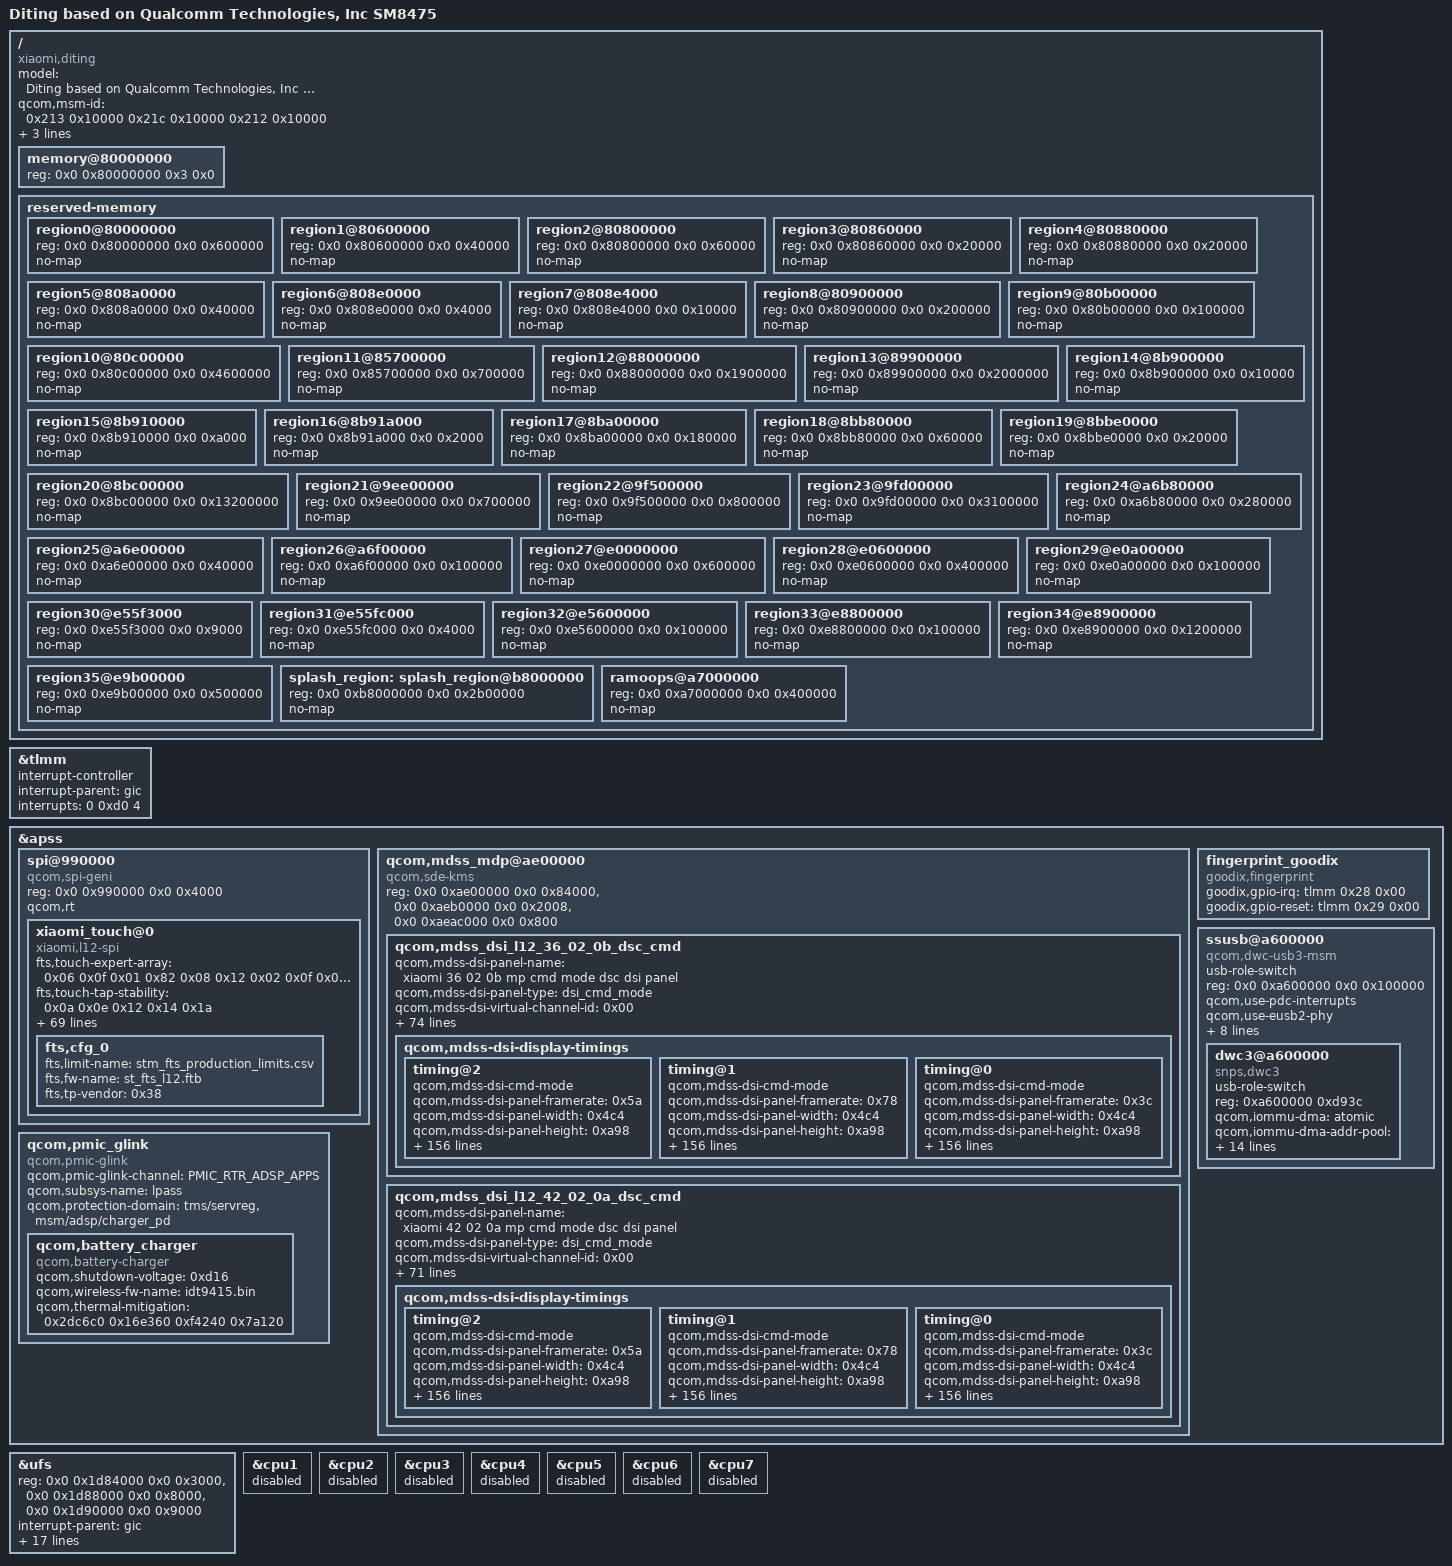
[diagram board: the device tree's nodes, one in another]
/dts-v1/;
/include/ "sm8475.dtsi"
/ {
    model = "Diting based on Qualcomm Technologies, Inc SM8475";
    compatible = "xiaomi,diting", "qcom,cape-mtp", "qcom,cape", "qcom,mtp";
    qcom,msm-id = <0x213 0x10000 0x21c 0x10000 0x212 0x10000>;
    qcom,board-id = <0x10008 0x00>;
    xiaomi,miboard-id = <0x0a 0x00>;
    interrupt-parent = <&gic>;

    /* 此节点供现有 ADT 生成器读取容量。原厂启动时内存并不连续；
       当前单段声明是构建占位，实际内存范围和保留区仍需核实。 */
    memory@80000000 { device_type = "memory"; reg = <0x0 0x80000000 0x3 0x0>; };
    reserved-memory {
        #address-cells = <2>;
        #size-cells = <2>;
        ranges;
        region0@80000000 { reg = <0x0 0x80000000 0x0 0x600000>; no-map; };
        region1@80600000 { reg = <0x0 0x80600000 0x0 0x40000>; no-map; };
        region2@80800000 { reg = <0x0 0x80800000 0x0 0x60000>; no-map; };
        region3@80860000 { reg = <0x0 0x80860000 0x0 0x20000>; no-map; };
        region4@80880000 { reg = <0x0 0x80880000 0x0 0x20000>; no-map; };
        region5@808a0000 { reg = <0x0 0x808a0000 0x0 0x40000>; no-map; };
        region6@808e0000 { reg = <0x0 0x808e0000 0x0 0x4000>; no-map; };
        region7@808e4000 { reg = <0x0 0x808e4000 0x0 0x10000>; no-map; };
        region8@80900000 { reg = <0x0 0x80900000 0x0 0x200000>; no-map; };
        region9@80b00000 { reg = <0x0 0x80b00000 0x0 0x100000>; no-map; };
        region10@80c00000 { reg = <0x0 0x80c00000 0x0 0x4600000>; no-map; };
        region11@85700000 { reg = <0x0 0x85700000 0x0 0x700000>; no-map; };
        region12@88000000 { reg = <0x0 0x88000000 0x0 0x1900000>; no-map; };
        region13@89900000 { reg = <0x0 0x89900000 0x0 0x2000000>; no-map; };
        region14@8b900000 { reg = <0x0 0x8b900000 0x0 0x10000>; no-map; };
        region15@8b910000 { reg = <0x0 0x8b910000 0x0 0xa000>; no-map; };
        region16@8b91a000 { reg = <0x0 0x8b91a000 0x0 0x2000>; no-map; };
        region17@8ba00000 { reg = <0x0 0x8ba00000 0x0 0x180000>; no-map; };
        region18@8bb80000 { reg = <0x0 0x8bb80000 0x0 0x60000>; no-map; };
        region19@8bbe0000 { reg = <0x0 0x8bbe0000 0x0 0x20000>; no-map; };
        region20@8bc00000 { reg = <0x0 0x8bc00000 0x0 0x13200000>; no-map; };
        region21@9ee00000 { reg = <0x0 0x9ee00000 0x0 0x700000>; no-map; };
        region22@9f500000 { reg = <0x0 0x9f500000 0x0 0x800000>; no-map; };
        region23@9fd00000 { reg = <0x0 0x9fd00000 0x0 0x3100000>; no-map; };
        region24@a6b80000 { reg = <0x0 0xa6b80000 0x0 0x280000>; no-map; };
        region25@a6e00000 { reg = <0x0 0xa6e00000 0x0 0x40000>; no-map; };
        region26@a6f00000 { reg = <0x0 0xa6f00000 0x0 0x100000>; no-map; };
        region27@e0000000 { reg = <0x0 0xe0000000 0x0 0x600000>; no-map; };
        region28@e0600000 { reg = <0x0 0xe0600000 0x0 0x400000>; no-map; };
        region29@e0a00000 { reg = <0x0 0xe0a00000 0x0 0x100000>; no-map; };
        region30@e55f3000 { reg = <0x0 0xe55f3000 0x0 0x9000>; no-map; };
        region31@e55fc000 { reg = <0x0 0xe55fc000 0x0 0x4000>; no-map; };
        region32@e5600000 { reg = <0x0 0xe5600000 0x0 0x100000>; no-map; };
        region33@e8800000 { reg = <0x0 0xe8800000 0x0 0x100000>; no-map; };
        region34@e8900000 { reg = <0x0 0xe8900000 0x0 0x1200000>; no-map; };
        region35@e9b00000 { reg = <0x0 0xe9b00000 0x0 0x500000>; no-map; };
        splash_region: splash_region@b8000000 { reg = <0x0 0xb8000000 0x0 0x2b00000>; no-map; };
        ramoops@a7000000 { reg = <0x0 0xa7000000 0x0 0x400000>; no-map; };
    };
};

/* 与本机运行时设备树中的 TLMM 中断控制器配置一致。 */
&tlmm {
    interrupt-controller;
    #interrupt-cells = <2>;
    interrupt-parent = <&gic>;
    interrupts = <0 0xd0 4>;
};

/* Board nodes from dtbo-02-0x0-r0.dtb (Redmi K50 Ultra), merged over the
   stock vendor_boot DTB. SoC containers (GENI SPI, MDSS, pmic_glink) are
   placeholders: only the board children are reproduced. */
&apss {
    spi@990000 {
        compatible = "qcom,spi-geni";
        reg = <0x0 0x990000 0x0 0x4000>;
        reg-names = "se_phys";
        #address-cells = <1>;
        #size-cells = <0>;
        qcom,rt;
        xiaomi_touch@0 {
            fts,touch-expert-array = <0x06 0x0f 0x01 0x82 0x08 0x12 0x02 0x0f 0x01 0x82 0x05 0x12 0x04 0x0f 0x01 0x82 0x04 0x12>;
            fts,touch-tap-stability = <0x0a 0x0e 0x12 0x14 0x1a>;
            fts,touch-aim-sensitivity = <0x0c 0x0a 0x08 0x06 0x04>;
            fts,touch-tap-sensitivity = <0xa0 0x96 0x8c 0x82 0x64>;
            fts,touch-follow-performance = <0x0a 0x0f 0x01 0x08 0x0f 0x01 0x06 0x0f 0x01 0x04 0x0f 0x01 0x02 0x0f 0x01>;
            fts,touch-normal-cornerzone-filter-hor2 = <0x00 0x00 0x405 0x00 0x4c3 0xbe 0x00 0x00 0x00 0x01 0x00 0x00 0x00 0x00 0x00 0x00 0x00 0x02 0x00 0x00 0x00 0x00 0x00 0x00 0x00 0x03 0x405 0x9d9 0x4c3 0xa97 0x00 0x00>;
            fts,touch-normal-cornerzone-filter-hor1 = <0x00 0x00 0x00 0x00 0x00 0x00 0x00 0x00 0x00 0x01 0x00 0x00 0xbe 0xbe 0x00 0x00 0x00 0x02 0x00 0x9d9 0xbe 0xa97 0x00 0x00 0x00 0x03 0x00 0x00 0x00 0x00 0x00 0x00>;
            fts,touch-normal-edgezone-filter-hor = <0x01 0x00 0x00 0x00 0x4c3 0x28 0x00 0x00 0x01 0x01 0x00 0xa6f 0x4c3 0xa97 0x00 0x00 0x01 0x02 0x00 0x00 0x28 0xa97 0x00 0x00 0x01 0x03 0x49b 0x00 0x4c3 0xa97 0x00 0x00>;
            fts,touch-cornerzone-filter-hor2 = <0x00 0x00 0x405 0x00 0x4c3 0xbe 0x00 0x00 0x00 0x01 0x00 0x00 0x00 0x00 0x00 0x00 0x00 0x02 0x00 0x00 0x00 0x00 0x00 0x00 0x00 0x03 0x405 0x9d9 0x4c3 0xa97 0x00 0x00>;
            fts,touch-cornerzone-filter-hor1 = <0x00 0x00 0x00 0x00 0x00 0x00 0x00 0x00 0x00 0x01 0x00 0x00 0xbe 0xbe 0x00 0x00 0x00 0x02 0x00 0x9d9 0xbe 0xa97 0x00 0x00 0x00 0x03 0x00 0x00 0x00 0x00 0x00 0x00>;
            fts,touch-cornerzone-filter-ver = <0x00 0x00 0x00 0x00 0x00 0x00 0x00 0x00 0x00 0x01 0x00 0x00 0x00 0x00 0x00 0x00 0x00 0x02 0x00 0x944 0xa9 0xa97 0x00 0x00 0x00 0x03 0x41a 0x944 0x4c3 0xa97 0x00 0x00>;
            fts,touch-edgezone-filter-hor = <0x01 0x00 0x00 0x00 0x4c3 0x2a 0x00 0x00 0x01 0x01 0x00 0xa6d 0x4c3 0xa97 0x00 0x00 0x01 0x02 0x00 0x00 0x2a 0xa97 0x00 0x00 0x01 0x03 0x499 0x00 0x4c3 0xa97 0x00 0x00>;
            fts,touch-edgezone-filter-ver = <0x01 0x00 0x00 0x00 0x00 0x00 0x00 0x00 0x01 0x01 0x00 0x00 0x00 0x00 0x00 0x00 0x01 0x02 0x00 0x00 0x2a 0xa97 0x00 0x00 0x01 0x03 0x499 0x00 0x4c3 0xa97 0x00 0x00>;
            fts,touch-deadzone-filter-hor = <0x02 0x00 0x00 0x00 0x4c3 0x00 0x00 0x00 0x02 0x01 0x00 0xa97 0x4c3 0xa97 0x00 0x00 0x02 0x02 0x00 0x00 0x00 0xa97 0x00 0x00 0x02 0x03 0x4c3 0x00 0x4c3 0xa97 0x00 0x00>;
            fts,touch-deadzone-filter-ver = <0x02 0x00 0x00 0x00 0x00 0x00 0x00 0x00 0x02 0x01 0x00 0x00 0x00 0x00 0x00 0x00 0x02 0x02 0x00 0x00 0x00 0xa97 0x00 0x00 0x02 0x03 0x4c3 0x00 0x4c3 0xa97 0x00 0x00>;
            fts,cornerfilter-area-step3 = <0x118>;
            fts,cornerfilter-area-step2 = <0xbe>;
            fts,cornerfilter-area-step1 = <0x70>;
            fts,touch-tap-stability-def = <0x03>;
            fts,touch-aim-sensitivity-def = <0x03>;
            fts,touch-tap-sensitivity-def = <0x04>;
            fts,touch-follow-performance-def = <0x03>;
            fts,support-super-resolution = <0x01>;
            fts,config-array-size = <0x01>;
            fts,non-curved-display = <0x01>;
            fts,default-fw-name = "st_fts_l12.ftb";
            fts,fod-y-size = <0x8e8>;
            fts,fod-x-size = <0x8e8>;
            fts,fod-ly = <0x5b04>;
            fts,fod-lx = <0x1360>;
            fts,support-fod = <0x01>;
            fts,y-max = <0x69f0>;
            fts,x-max = <0x2fa8>;
            fts,irq-flags = <0x2008>;
            fts,reset-gpio-name = "fts_rst";
            fts,reset-gpio = <&tlmm 0x14 0x00>;
            fts,reset-gpio-enable;
            fts,irq-gpio-name = "fts_irq";
            fts,irq-gpio = <&tlmm 0x15 0x2008>;
            fts,bus-reg-name = "vdd";
            fts,avdd-gpio = <&tlmm 0x47 0x00>;
            goodix,touch-expert-array = <0x02 0x03 0x02 0x02 0x04 0x03 0x03 0x02 0x03 0x03 0x04 0x02>;
            goodix,config-name = "goodix_cfg_group_l12";
            goodix,firmware-name = "goodix_firmware_l12";
            goodix,panel-max-p = <0x1000>;
            goodix,panel-max-w = <0xff>;
            goodix,panel-max-y = <0x69f0>;
            goodix,panel-max-x = <0x2fa8>;
            goodix,irq-flags = <0x02>;
            goodix,reset-gpio = <&tlmm 0x14 0x00>;
            goodix,irq-gpio = <&tlmm 0x15 0x2008>;
            goodix,iovdd-name = "vdd";
            goodix,avdd-gpio = <&tlmm 0x47 0x00>;
            interrupts = <0x15 0x2008>;
            interrupt-parent = <&tlmm>;
            spi-max-frequency = <0xb71b00>;
            reg = <0x00>;
            compatible = "xiaomi,l12-spi";
            status = "ok";
            fts,cfg_0 {
                fts,limit-name = "stm_fts_production_limits.csv";
                fts,fw-name = "st_fts_l12.ftb";
                fts,tp-vendor = <0x38>;
            };
        };
    };

    qcom,mdss_mdp@ae00000 {
        compatible = "qcom,sde-kms";
        reg = <0x0 0xae00000 0x0 0x84000>,
              <0x0 0xaeb0000 0x0 0x2008>,
              <0x0 0xaeac000 0x0 0x800>;
        reg-names = "mdp_phys", "vbif_phys", "regdma_phys";
        qcom,mdss_dsi_l12_36_02_0b_dsc_cmd {
            qcom,mdss-dsi-panel-name = "xiaomi 36 02 0b mp cmd mode dsc dsi panel";
            qcom,mdss-dsi-panel-type = "dsi_cmd_mode";
            qcom,mdss-dsi-virtual-channel-id = <0x00>;
            qcom,mdss-dsi-stream = <0x00>;
            qcom,mdss-dsi-bpp = <0x1e>;
            qcom,mdss-dsi-color-order = "rgb_swap_rgb";
            qcom,mdss-dsi-underflow-color = <0xff>;
            qcom,mdss-dsi-border-color = <0x00>;
            qcom,dsi-ctrl-num = <0x00>;
            qcom,dsi-phy-num = <0x00>;
            qcom,mdss-dsi-traffic-mode = "burst_mode";
            qcom,mdss-dsi-lane-map = "lane_map_0123";
            qcom,mdss-dsi-bllp-eof-power-mode;
            qcom,mdss-dsi-bllp-power-mode;
            qcom,mdss-dsi-lane-0-state;
            qcom,mdss-dsi-lane-1-state;
            qcom,mdss-dsi-lane-2-state;
            qcom,mdss-dsi-lane-3-state;
            qcom,mdss-dsi-dma-trigger = "trigger_sw";
            qcom,mdss-dsi-mdp-trigger = "none";
            qcom,mdss-dsi-reset-sequence = <0x01 0x0b 0x00 0x01 0x01 0x14>;
            qcom,mdss-pan-physical-width-dimension = <0x2b7>;
            qcom,mdss-pan-physical-height-dimension = <0x609>;
            qcom,mdss-dsi-te-pin-select = <0x01>;
            qcom,mdss-dsi-wr-mem-start = <0x2c>;
            qcom,mdss-dsi-wr-mem-continue = <0x3c>;
            qcom,mdss-dsi-te-dcs-command = <0x01>;
            qcom,mdss-dsi-te-check-enable;
            qcom,mdss-dsi-te-using-te-pin;
            qcom,mdss-dsi-tx-eot-append;
            qcom,mdss-dsi-lp11-init;
            qcom,mdss-dsi-bl-inverted-dbv;
            qcom,bl-update-flag = "delay_until_first_frame";
            qcom,mdss-dsi-panel-mode-switch;
            qcom,mdss-dsi-panel-hdr-enabled;
            qcom,mdss-dsi-panel-hdr-color-primaries = <0x38a4 0x3c8c 0x7d00 0x4268 0x3c8c 0x7530 0x1f40 0xbb8>;
            qcom,mdss-dsi-panel-peak-brightness = <0x401640>;
            qcom,mdss-dsi-panel-blackness-level = <0xc9e>;
            qcom,mdss-dsi-dma-schedule-line = <0x01>;
            qcom,mdss-dsi-dma-schedule-window = <0x0a>;
            mi,panel-id = <0x4c3132 0x360200>;
            mi,esd-err-irq-gpio = <&tlmm 0x74 0x2008>;
            mi,thermal-dimming-flag;
            mi,panel-on-dimming-delay = <0x78>;
            mi,dimming-need-update-speed;
            mi,dimming-node = <0x00 0xc8 0x1c2 0x320 0xfff>;
            mi,max-brightness-clone = <0xfff>;
            mi,normal-max-brightness-clone = <0x7ff>;
            mi,mdss-dsi-fac-bl-max-level = <0x7ff>;
            mi,mdss-fac-brightness-max-level = <0x7ff>;
            mi,hbm-bl-min-level = <0x01>;
            mi,hbm-bl-max-level = <0x7ff>;
            mi,local-hbm-enabled;
            mi,local-hbm-white-1000nit-update-flag;
            mi,local-hbm-white-110nit-update-flag;
            mi,local-hbm-alpha-ctrl-aa-area;
            mi,local-hbm-ctrl-df-reg;
            mi,doze-hbm-dbv-level = <0xfc>;
            mi,doze-lbm-dbv-level = <0x14>;
            mi,ddic-round-corner-enabled;
            mi,fod-low-brightness-clone-threshold = <0xc8>;
            mi,fod-low-brightness-lux-threshold = <0x03>;
            mi,flat-update-flag;
            mi,flat-need-sync-te;
            mi,flat-need-update-gamma-zero;
            mi,local-hbm-ui-ready-delay-num-frame = <0x04>;
            qcom,mdss-dsi-bl-pmic-control-type = "bl_ctrl_dcs";
            qcom,mdss-dsi-bl-min-level = <0x01>;
            qcom,mdss-dsi-bl-max-level = <0xfff>;
            qcom,mdss-brightness-max-level = <0xfff>;
            qcom,platform-reset-gpio = <&tlmm 0x00 0x00>;
            qcom,ulps-enabled;
            qcom,dsi-select-clocks = "pll_byte_clk0", "pll_dsi_clk0";
            qcom,mdss-dsi-display-timings {
                timing@2 {
                    qcom,mdss-dsi-cmd-mode;
                    qcom,mdss-dsi-panel-framerate = <0x5a>;
                    qcom,mdss-dsi-panel-width = <0x4c4>;
                    qcom,mdss-dsi-panel-height = <0xa98>;
                    qcom,mdss-dsi-h-front-porch = <0x10>;
                    qcom,mdss-dsi-h-back-porch = <0x56>;
                    qcom,mdss-dsi-h-pulse-width = <0x10>;
                    qcom,mdss-dsi-h-sync-skew = <0x00>;
                    qcom,mdss-dsi-v-back-porch = <0x10>;
                    qcom,mdss-dsi-v-front-porch = <0x18>;
                    qcom,mdss-dsi-v-pulse-width = <0x04>;
                    qcom,mdss-dsi-h-sync-pulse = <0x00>;
                    qcom,mdss-dsi-h-left-border = <0x00>;
                    qcom,mdss-dsi-h-right-border = <0x00>;
                    qcom,mdss-dsi-v-top-border = <0x00>;
                    qcom,mdss-dsi-v-bottom-border = <0x00>;
                    qcom,mdss-dsi-panel-clockrate = <0x4190ab00>;
                    qcom,mdss-dsi-panel-jitter = <0x05 0x01>;
                    qcom,mdss-mdp-transfer-time-us = <0x1c84>;
                    qcom,mdss-dsi-on-command = [39 00 00 00 00 00 06 f0 55 aa 52 08 08 39 00 00 40 00 00 06 e0 41 73 73 73 83 39 00 00 40 00 00 16 e1 00 00 00 00 00 00 00 00 00 00 00 00 00 00 00 00 00 00 00 00 00 39 00 00 40 00 00 16 e2 80 ef 66 86 00 00 00 00 00 00 00 00 00 00 00 00 00 00 02 01 00 39 00 00 40 00 00 16 e3 00 00 00 00 00 00 00 00 00 00 00 00 00 00 00 00 00 00 00 00 00 39 00 00 40 00 00 13 e4 00 00 00 00 00 00 00 00 00 00 00 00 00 00 00 00 00 00 39 00 00 40 00 00 13 e5 00 00 00 00 00 00 00 00 00 00 00 00 00 00 00 00 00 00 39 00 00 00 00 00 13 e6 00 00 00 00 00 00 00 00 00 00 00 00 00 00 00 00 00 00 39 00 00 40 00 00 06 f0 55 aa 52 08 07 15 00 00 40 00 00 02 6f 37 39 00 00 40 00 00 04 b7 08 08 08 39 00 00 40 00 00 06 f0 55 aa 52 08 00 15 00 00 40 00 00 02 6f 37 39 00 00 40 00 00 04 b7 08 08 08 39 00 00 40 00 00 06 f0 55 aa 52 08 00 15 00 00 40 00 00 02 6f 01 15 00 00 40 00 00 02 c0 20 39 00 00 40 00 00 06 f0 55 aa 52 08 08 39 00 00 40 00 00 22 ea 02 00 e0 00 e0 70 00 70 00 00 00 00 00 00 00 00 00 00 00 00 00 00 00 00 00 00 00 00 00 00 00 00 00 15 00 00 40 00 00 02 6f 15 39 00 00 40 00 00 07 ea 00 00 80 00 80 00 39 00 00 40 00 00 06 f0 55 aa 52 08 08 15 00 00 40 00 00 02 6f 21 39 00 00 00 00 00 07 ea 00 00 00 00 00 00 39 00 00 40 00 00 06 f0 55 aa 52 08 08 15 00 00 40 00 00 02 e0 01 39 00 00 40 00 00 05 e2 42 ee 04 20 15 00 00 40 00 00 02 6f 12 39 00 00 40 00 00 03 e2 fd 03 39 00 00 40 00 00 09 ea 02 00 b8 00 b8 58 00 58 15 00 00 40 00 00 02 6f 17 39 00 00 00 00 00 04 ea 48 00 48 39 00 00 40 00 00 06 f0 55 aa 52 08 00 15 00 00 40 00 00 02 6f 13 15 00 00 00 00 00 02 b2 4f 39 00 00 40 00 00 05 ff aa 55 a5 81 15 00 00 40 00 00 02 6f 19 15 00 00 40 00 00 02 fb 00 15 00 00 40 00 00 02 6f 05 15 00 00 00 00 00 02 fe 34 39 00 00 40 00 00 05 ff aa 55 a5 80 15 00 00 40 00 00 02 6f 1a 15 00 00 40 00 00 02 f4 55 15 00 00 40 00 00 02 6f 0f 15 00 00 40 00 00 02 fc 00 15 00 00 40 00 00 02 6f 09 39 00 00 00 00 00 03 fc fc f0 39 00 00 40 00 00 05 ff aa 55 a5 83 15 00 00 40 00 00 02 6f 12 15 00 00 00 00 00 02 fe 41 15 00 00 40 00 00 02 5f 01 15 00 00 40 00 00 02 26 00 15 00 00 00 00 00 02 17 10 39 00 00 40 00 00 05 2a 00 00 04 c3 39 00 00 00 00 00 05 2b 00 00 0a 97 15 00 00 00 00 00 02 2f 01 15 00 00 40 00 00 02 35 30 39 00 00 40 00 00 03 44 00 00 39 00 00 40 00 00 03 51 00 00 15 00 00 40 00 00 02 6f 04 39 00 00 40 00 00 03 51 03 ff 15 00 00 00 00 00 02 53 20 15 00 00 40 00 00 02 90 03 39 00 00 40 00 00 13 91 ab 28 00 0c d2 00 02 4c 01 24 00 08 09 75 07 7b 10 f0 39 00 00 40 00 00 05 ff aa 55 a5 81 15 00 00 40 00 00 02 6f 0b 15 00 00 40 00 00 02 fd 80 39 00 00 40 00 00 05 ff aa 55 a5 81 15 00 00 40 00 00 02 6f 0e 15 00 00 00 00 00 02 f5 00 39 00 00 40 00 00 05 ff aa 55 a5 80 15 00 00 40 00 00 02 6f 15 39 00 00 40 00 00 03 f8 01 68 15 00 00 40 00 00 02 6f 31 39 00 00 40 00 00 03 f8 01 0e 15 00 00 40 00 00 02 6f 01 15 00 00 00 00 00 02 1f 06 39 00 00 40 00 00 05 ff aa 55 a5 80 15 00 00 40 00 00 02 6f 31 39 00 00 40 00 00 03 f8 01 0c 39 00 00 40 00 00 05 ff aa 55 a5 80 15 00 00 40 00 00 02 6f 15 39 00 00 40 00 00 03 f8 01 5f 39 00 00 40 00 00 06 f0 55 aa 52 08 01 39 00 00 00 00 00 2a c3 dd 06 22 11 ff 00 06 20 11 ff 00 04 01 11 05 95 18 04 01 11 05 95 18 04 01 11 05 95 18 04 01 11 05 95 18 04 01 11 05 95 18 39 00 00 40 00 00 06 f0 55 aa 52 08 00 39 00 00 40 00 00 02 6f 01 39 00 00 40 00 00 02 be 45 39 00 00 40 00 00 02 6f 05 39 00 00 00 00 00 02 be 88 39 01 00 40 00 00 06 f0 55 aa 52 08 00 15 01 00 40 00 00 02 b2 09 15 01 00 40 00 00 02 6f 05 39 01 00 00 00 00 03 b2 08 08 39 00 00 40 00 00 06 f0 55 aa 52 08 00 15 00 00 40 00 00 02 e2 40 15 00 00 40 00 00 02 6f 57 39 00 00 40 00 00 06 e2 ff ff ff ff ff 15 00 00 40 00 00 02 6f 37 39 00 00 00 00 00 05 e2 80 08 08 0c 39 00 00 40 00 00 06 f0 55 aa 52 08 01 15 00 00 00 00 00 02 dd 40 39 00 00 40 00 00 06 f0 55 aa 52 08 00 39 00 00 00 00 00 11 c6 ad aa aa a3 ad aa aa a3 ad aa aa a3 ad aa aa a3 39 00 00 40 00 00 05 ff aa 55 a5 80 15 00 00 40 00 00 02 6f 0a 39 00 00 40 00 00 04 f6 70 70 70 15 00 00 40 00 00 02 6f 0e 15 00 00 40 00 00 02 f6 70 15 00 00 40 00 00 02 6f 2d 15 00 00 00 00 00 02 fc 44 39 00 00 40 00 00 06 f0 55 aa 52 08 01 15 00 00 40 00 00 02 6f 01 39 00 00 40 00 00 05 d2 00 00 00 20 39 00 00 40 00 00 04 e4 80 05 5c 15 00 00 40 00 00 02 6f 07 39 00 00 40 00 00 03 e4 05 5c 15 00 00 40 00 00 02 6f 0a 39 00 00 40 00 00 04 e4 80 05 5c 15 00 00 40 00 00 02 6f 21 39 00 00 40 00 00 04 d8 60 60 60 15 00 00 40 00 00 02 6f 1e 15 00 00 40 00 00 02 d8 24 15 00 00 00 00 00 02 cd 61 39 00 00 40 00 00 06 f0 55 aa 52 08 05 39 00 00 40 00 00 03 b3 84 85 39 00 00 40 00 00 03 b5 84 85 39 00 00 40 00 00 05 b7 84 00 00 84 39 00 00 00 00 00 05 b8 84 00 00 84 39 00 00 40 00 00 06 f0 55 aa 52 08 00 15 00 00 40 00 00 02 6f 07 39 00 00 00 00 00 04 ca 08 06 58 05 00 00 00 78 00 02 11 00 05 00 00 00 00 00 02 29 00];
                    qcom,mdss-dsi-off-command = [05 00 00 00 00 00 02 28 00 05 00 00 00 64 00 02 10 00];
                    qcom,mdss-dsi-on-command-state = "dsi_lp_mode";
                    qcom,mdss-dsi-off-command-state = "dsi_lp_mode";
                    qcom,mdss-dsi-timing-switch-command = [15 00 00 00 00 00 02 2f 01 39 00 00 40 00 00 06 f0 55 aa 52 08 08 15 00 00 40 00 00 02 e0 01 39 00 00 40 00 00 05 e2 42 ee 04 20 15 00 00 40 00 00 02 6f 12 39 00 00 40 00 00 03 e2 fd 03 39 00 00 40 00 00 09 ea 02 00 b8 00 b8 58 00 58 15 00 00 40 00 00 02 6f 17 39 00 00 00 00 00 04 ea 48 00 48];
                    qcom,mdss-dsi-timing-switch-command-update = <0x2f 0x00 0x01>;
                    qcom,mdss-dsi-timing-switch-command-state = "dsi_hs_mode";
                    qcom,mdss-dsi-nolp-command = [39 00 00 00 00 00 06 f0 55 aa 52 08 01 15 00 00 00 00 00 02 c3 dd 15 00 00 00 00 00 02 65 00 15 00 00 00 00 00 02 38 00 39 00 00 00 00 00 07 51 00 fc 00 00 03 ff 15 00 00 00 00 00 02 2c 00 39 00 00 00 00 00 06 f0 55 aa 52 08 00 39 00 00 00 00 00 02 6f 01 39 00 00 00 00 00 02 be 45];
                    qcom,mdss-dsi-nolp-command-update = <0x51 0x04 0x02>;
                    qcom,mdss-dsi-nolp-command-state = "dsi_lp_mode";
                    qcom,compression-mode = "dsc";
                    qcom,mdss-dsc-config-by-manufacture-cmd;
                    qcom,mdss-dsc-version = <0x11>;
                    qcom,mdss-dsc-scr-version = <0x01>;
                    qcom,mdss-dsc-slice-height = <0x0c>;
                    qcom,mdss-dsc-slice-width = <0x262>;
                    qcom,mdss-dsc-slice-per-pkt = <0x02>;
                    qcom,mdss-dsc-bit-per-component = <0x0a>;
                    qcom,mdss-dsc-bit-per-pixel = <0x08>;
                    qcom,mdss-dsc-block-prediction-enable;
                    mi,mdss-flat-status-control-gamma-cfg = <0x04 0x01>;
                    mi,mdss-dsi-dimmingon-command = [39 00 00 00 00 00 02 53 28];
                    mi,mdss-dsi-dimmingon-command-state = "dsi_hs_mode";
                    mi,mdss-dsi-dimmingoff-command = [39 00 00 00 00 00 02 53 20];
                    mi,mdss-dsi-dimmingoff-command-state = "dsi_hs_mode";
                    mi,mdss-dsi-hbm-fod-on-command = <0x39000000 0x551 0xfff0000>;
                    mi,mdss-dsi-hbm-fod-on-command-state = "dsi_lp_mode";
                    mi,mdss-dsi-hbm-fod-off-command = <0x39000000 0x551 0x7ff0000>;
                    mi,mdss-dsi-hbm-fod-off-command-state = "dsi_lp_mode";
                    mi,mdss-dsi-hbm-fod-off-command-update = <0x51 0x00 0x02>;
                    mi,mdss-dsi-local-hbm-normal-white-1000nit-command = [39 00 00 40 00 00 06 f0 55 aa 52 08 00 39 00 00 40 00 00 02 6f 31 39 00 00 40 00 00 02 df 22 39 00 00 40 00 00 06 f0 55 aa 52 08 02 39 00 00 40 00 00 07 d0 09 30 08 1c 0a 30 39 00 00 40 00 00 06 f0 55 aa 52 08 00 39 00 00 40 00 00 02 6f 4c 39 00 00 40 00 00 03 df 05 20 39 00 00 40 00 00 06 88 01 02 62 09 8c 39 00 00 00 00 00 04 87 25 11 11];
                    mi,mdss-dsi-local-hbm-normal-white-1000nit-command-update = <0x87 0x09 0x03 0xd0 0x04 0x06 0xdf 0x07 0x02>;
                    mi,mdss-dsi-local-hbm-normal-white-1000nit-command-state = "dsi_hs_mode";
                    mi,mdss-dsi-local-hbm-hlpm-white-1000nit-command = [15 00 00 00 00 00 02 65 00 15 00 00 00 00 00 02 38 00 39 00 00 00 00 00 07 51 00 00 00 00 03 ff 15 00 00 00 00 00 02 2c 00 39 00 00 40 00 00 06 f0 55 aa 52 08 00 39 00 00 40 00 00 02 6f 31 39 00 00 40 00 00 02 df 22 39 00 00 40 00 00 06 f0 55 aa 52 08 02 39 00 00 40 00 00 07 d0 09 30 08 1c 0a 30 39 00 00 40 00 00 06 f0 55 aa 52 08 00 39 00 00 40 00 00 02 6f 4c 39 00 00 40 00 00 03 df 05 20 39 00 00 40 00 00 06 88 01 02 62 09 8c 39 00 00 00 00 00 04 87 25 11 11];
                    mi,mdss-dsi-local-hbm-hlpm-white-1000nit-command-update = <0x87 0x0d 0x03 0xd0 0x08 0x06>;
                    mi,mdss-dsi-local-hbm-hlpm-white-1000nit-command-state = "dsi_hs_mode";
                    mi,mdss-dsi-local-hbm-normal-white-110nit-command = [39 00 00 40 00 00 06 f0 55 aa 52 08 00 39 00 00 40 00 00 02 6f 31 39 00 00 40 00 00 02 df 22 39 00 00 40 00 00 06 f0 55 aa 52 08 02 39 00 00 40 00 00 07 d0 06 55 05 cc 07 1f 39 00 00 40 00 00 06 f0 55 aa 52 08 00 39 00 00 40 00 00 02 6f 4c 39 00 00 40 00 00 03 df 05 20 39 00 00 40 00 00 06 88 01 02 62 09 8c 39 00 00 00 00 00 04 87 25 11 11];
                    mi,mdss-dsi-local-hbm-normal-white-110nit-command-update = <0x87 0x09 0x03 0xd0 0x04 0x06>;
                    mi,mdss-dsi-local-hbm-normal-white-110nit-command-state = "dsi_hs_mode";
                    mi,mdss-dsi-local-hbm-hlpm-white-110nit-command = [15 00 00 00 00 00 02 65 00 15 00 00 00 00 00 02 38 00 39 00 00 00 00 00 07 51 00 00 00 00 01 ff 15 00 00 00 00 00 02 2c 00 39 00 00 40 00 00 06 f0 55 aa 52 08 00 39 00 00 40 00 00 02 6f 31 39 00 00 40 00 00 02 df 22 39 00 00 40 00 00 06 f0 55 aa 52 08 02 39 00 00 40 00 00 07 d0 06 55 05 cc 07 1f 39 00 00 40 00 00 06 f0 55 aa 52 08 00 39 00 00 40 00 00 02 6f 4c 39 00 00 40 00 00 03 df 05 20 39 00 00 40 00 00 06 88 01 02 62 09 8c 39 00 00 00 00 00 04 87 25 11 11];
                    mi,mdss-dsi-local-hbm-hlpm-white-110nit-command-update = <0x87 0x0d 0x03 0xd0 0x08 0x06>;
                    mi,mdss-dsi-local-hbm-hlpm-white-110nit-command-state = "dsi_hs_mode";
                    mi,mdss-dsi-local-hbm-normal-green-500nit-command = [39 00 00 00 00 00 06 f0 55 aa 52 08 00 39 00 00 40 00 00 02 6f 31 39 00 00 40 00 00 02 df 22 39 00 00 40 00 00 06 f0 55 aa 52 08 02 39 00 00 40 00 00 07 d0 00 00 07 bc 00 00 39 00 00 00 00 00 06 f0 55 aa 52 08 00 39 00 00 40 00 00 02 6f 4c 39 00 00 40 00 00 03 df 05 20 39 00 00 40 00 00 06 88 01 02 62 09 8c 39 00 00 00 00 00 04 87 25 11 11];
                    mi,mdss-dsi-local-hbm-normal-green-500nit-command-update = <0x87 0x09 0x03 0xdf 0x07 0x02>;
                    mi,mdss-dsi-local-hbm-normal-green-500nit-command-state = "dsi_lp_mode";
                    mi,mdss-dsi-local-hbm-off-to-normal-command = <0x39000000 0x253 0x20390000 0x40000003 0x5107ff39 0x00 0x28700>;
                    mi,mdss-dsi-local-hbm-off-to-normal-command-update = <0x51 0x01 0x02>;
                    mi,mdss-dsi-local-hbm-off-to-normal-command-state = "dsi_hs_mode";
                    mi,mdss-dsi-local-hbm-off-to-hbm-command = [39 00 00 00 00 00 03 51 07 ff 39 00 00 00 00 00 02 87 00];
                    mi,mdss-dsi-local-hbm-off-to-hbm-command-update = <0x51 0x00 0x02>;
                    mi,mdss-dsi-local-hbm-off-to-hbm-command-state = "dsi_hs_mode";
                    mi,mdss-dsi-local-hbm-off-to-hlpm-command = <0x39000000 0x351 0x3900 0x00 0x2870039 0x4000 0x75100 0x03 0xff150000 0x40000002 0x39001500 0x400000 0x2650115 0x00 0x22c00>;
                    mi,mdss-dsi-local-hbm-off-to-hlpm-command-state = "dsi_hs_mode";
                    mi,mdss-dsi-local-hbm-off-to-llpm-command = [39 00 00 00 00 00 03 51 00 00 39 00 00 00 00 00 02 87 00 15 00 00 40 00 00 02 6f 04 39 00 00 40 00 00 03 51 01 ff 15 00 00 40 00 00 02 39 00 15 00 00 40 00 00 02 65 01 15 00 00 00 00 00 02 2c 00];
                    mi,mdss-dsi-local-hbm-off-to-llpm-command-state = "dsi_hs_mode";
                    mi,mdss-dsi-doze-hbm-command = [39 00 00 40 00 00 06 f0 55 aa 52 08 01 15 00 00 40 00 00 02 c3 00 39 00 00 40 00 00 06 f0 55 aa 52 08 00 39 00 00 40 00 00 02 6f 01 39 00 00 40 00 00 02 be 41 39 00 00 40 00 00 07 51 00 00 00 00 03 ff 15 00 00 40 00 00 02 39 00 15 00 00 40 00 00 02 65 01 15 00 00 00 00 00 02 2c 00];
                    mi,mdss-dsi-doze-hbm-command-state = "dsi_lp_mode";
                    mi,mdss-dsi-doze-lbm-command = [39 00 00 40 00 00 06 f0 55 aa 52 08 01 15 00 00 40 00 00 02 c3 00 39 00 00 40 00 00 06 f0 55 aa 52 08 00 39 00 00 40 00 00 02 6f 01 39 00 00 40 00 00 02 be 41 15 00 00 40 00 00 02 6f 04 39 00 00 40 00 00 03 51 01 ff 15 00 00 40 00 00 02 39 00 15 00 00 40 00 00 02 65 01 15 00 00 00 00 00 02 2c 00];
                    mi,mdss-dsi-doze-lbm-command-state = "dsi_lp_mode";
                    mi,mdss-dsi-doze-hbm-nolp-command = [39 00 00 00 00 00 06 f0 55 aa 52 08 01 15 00 00 00 00 00 02 c3 dd 15 00 00 00 00 00 02 65 00 15 00 00 00 00 00 02 38 00 39 00 00 00 00 00 07 51 00 fc 00 00 03 ff 15 00 00 00 00 00 02 2c 00 39 00 00 00 00 00 06 f0 55 aa 52 08 00 39 00 00 00 00 00 02 6f 01 39 00 00 00 00 00 02 be 45];
                    mi,mdss-dsi-doze-hbm-nolp-command-state = "dsi_lp_mode";
                    mi,mdss-dsi-doze-lbm-nolp-command = [39 00 00 00 00 00 06 f0 55 aa 52 08 01 15 00 00 00 00 00 02 c3 dd 15 00 00 00 00 00 02 65 00 15 00 00 00 00 00 02 38 00 39 00 00 00 00 00 07 51 00 14 00 00 01 ff 15 00 00 00 00 00 02 2c 00 39 00 00 00 00 00 06 f0 55 aa 52 08 00 39 00 00 00 00 00 02 6f 01 39 00 00 00 00 00 02 be 45];
                    mi,mdss-dsi-doze-lbm-nolp-command-state = "dsi_lp_mode";
                    mi,mdss-dsi-flat-mode-on-command = [15 00 00 00 00 00 02 5f 00 15 00 00 00 00 00 02 2f 04];
                    mi,mdss-dsi-flat-mode-on-command-state = "dsi_lp_mode";
                    mi,mdss-dsi-flat-mode-off-command = [15 00 00 00 00 00 02 5f 01 15 00 00 00 00 00 02 2f 01];
                    mi,mdss-dsi-flat-mode-off-command-state = "dsi_lp_mode";
                    mi,mdss-dsi-round-corner-on-command = [39 00 00 00 00 00 06 f0 55 aa 52 08 07 39 00 00 00 00 00 02 c0 a1];
                    mi,mdss-dsi-round-corner-on-command-state = "dsi_lp_mode";
                    mi,mdss-dsi-round-corner-off-command = [39 00 00 00 00 00 06 f0 55 aa 52 08 07 39 00 00 40 00 00 02 c0 07 39 00 00 40 00 00 02 c1 00 39 00 00 40 00 00 02 c2 00 39 00 00 40 00 00 02 c3 00 39 00 00 40 00 00 02 c4 00 39 00 00 40 00 00 02 c5 00 39 00 00 40 00 00 02 c6 00 39 00 00 40 00 00 02 c7 00 39 00 00 40 00 00 02 c8 00 39 00 00 40 00 00 02 c9 00 39 00 00 40 00 00 02 ca 00 39 00 00 40 00 00 02 cb 00 39 00 00 00 00 00 02 cc 00];
                    mi,mdss-dsi-round-corner-off-command-state = "dsi_lp_mode";
                    mi,mdss-dsi-dimming-8frame-command = <0x39000000 0x6f0 0x55aa5208 0x150000 0x02 0x6f053900 0x00 0x3b20808>;
                    mi,mdss-dsi-dimming-8frame-command-state = "dsi_lp_mode";
                    mi,mdss-dsi-dimming-4frame-command = <0x39000000 0x6f0 0x55aa5208 0x150000 0x02 0x6f053900 0x00 0x3b20404>;
                    mi,mdss-dsi-dimming-4frame-command-state = "dsi_lp_mode";
                    qcom,mdss-dsi-panel-phy-timings = [00 24 0a 0a 1a 25 09 0a 09 02 04 00 1e 0f];
                    qcom,display-topology = <0x01 0x01 0x01>;
                    qcom,default-topology-index = <0x00>;
                };
                timing@1 {
                    qcom,mdss-dsi-cmd-mode;
                    qcom,mdss-dsi-panel-framerate = <0x78>;
                    qcom,mdss-dsi-panel-width = <0x4c4>;
                    qcom,mdss-dsi-panel-height = <0xa98>;
                    qcom,mdss-dsi-h-front-porch = <0x10>;
                    qcom,mdss-dsi-h-back-porch = <0x56>;
                    qcom,mdss-dsi-h-pulse-width = <0x10>;
                    qcom,mdss-dsi-h-sync-skew = <0x00>;
                    qcom,mdss-dsi-v-back-porch = <0x10>;
                    qcom,mdss-dsi-v-front-porch = <0x18>;
                    qcom,mdss-dsi-v-pulse-width = <0x04>;
                    qcom,mdss-dsi-h-sync-pulse = <0x00>;
                    qcom,mdss-dsi-h-left-border = <0x00>;
                    qcom,mdss-dsi-h-right-border = <0x00>;
                    qcom,mdss-dsi-v-top-border = <0x00>;
                    qcom,mdss-dsi-v-bottom-border = <0x00>;
                    qcom,mdss-dsi-panel-clockrate = <0x4190ab00>;
                    qcom,mdss-dsi-panel-jitter = <0x05 0x01>;
                    qcom,mdss-mdp-transfer-time-us = <0x1c84>;
                    qcom,mdss-dsi-on-command = [39 00 00 00 00 00 06 f0 55 aa 52 08 08 39 00 00 40 00 00 06 e0 41 73 73 73 83 39 00 00 40 00 00 16 e1 00 00 00 00 00 00 00 00 00 00 00 00 00 00 00 00 00 00 00 00 00 39 00 00 40 00 00 16 e2 80 ef 66 86 00 00 00 00 00 00 00 00 00 00 00 00 00 00 02 01 00 39 00 00 40 00 00 16 e3 00 00 00 00 00 00 00 00 00 00 00 00 00 00 00 00 00 00 00 00 00 39 00 00 40 00 00 13 e4 00 00 00 00 00 00 00 00 00 00 00 00 00 00 00 00 00 00 39 00 00 40 00 00 13 e5 00 00 00 00 00 00 00 00 00 00 00 00 00 00 00 00 00 00 39 00 00 00 00 00 13 e6 00 00 00 00 00 00 00 00 00 00 00 00 00 00 00 00 00 00 39 00 00 40 00 00 06 f0 55 aa 52 08 07 15 00 00 40 00 00 02 6f 37 39 00 00 40 00 00 04 b7 08 08 08 39 00 00 40 00 00 06 f0 55 aa 52 08 00 15 00 00 40 00 00 02 6f 37 39 00 00 40 00 00 04 b7 08 08 08 39 00 00 40 00 00 06 f0 55 aa 52 08 00 15 00 00 40 00 00 02 6f 01 15 00 00 40 00 00 02 c0 20 39 00 00 40 00 00 06 f0 55 aa 52 08 08 39 00 00 40 00 00 22 ea 02 00 e0 00 e0 70 00 70 00 00 00 00 00 00 00 00 00 00 00 00 00 00 00 00 00 00 00 00 00 00 00 00 00 15 00 00 40 00 00 02 6f 15 39 00 00 40 00 00 07 ea 00 00 80 00 80 00 39 00 00 40 00 00 06 f0 55 aa 52 08 08 15 00 00 40 00 00 02 6f 21 39 00 00 00 00 00 07 ea 00 00 00 00 00 00 39 00 00 40 00 00 06 f0 55 aa 52 08 08 15 00 00 40 00 00 02 e0 01 39 00 00 40 00 00 05 e2 d6 4e 84 88 15 00 00 40 00 00 02 6f 12 39 00 00 40 00 00 03 e2 fd 03 39 00 00 40 00 00 09 ea 02 00 e0 00 e0 80 00 80 15 00 00 40 00 00 02 6f 17 39 00 00 00 00 00 04 ea 38 00 38 39 00 00 40 00 00 06 f0 55 aa 52 08 00 15 00 00 40 00 00 02 6f 13 15 00 00 00 00 00 02 b2 4f 39 00 00 40 00 00 05 ff aa 55 a5 81 15 00 00 40 00 00 02 6f 19 15 00 00 40 00 00 02 fb 00 15 00 00 40 00 00 02 6f 05 15 00 00 00 00 00 02 fe 34 39 00 00 40 00 00 05 ff aa 55 a5 80 15 00 00 40 00 00 02 6f 1a 15 00 00 40 00 00 02 f4 55 15 00 00 40 00 00 02 6f 0f 15 00 00 40 00 00 02 fc 00 15 00 00 40 00 00 02 6f 09 39 00 00 00 00 00 03 fc fc f0 39 00 00 40 00 00 05 ff aa 55 a5 83 15 00 00 40 00 00 02 6f 12 15 00 00 00 00 00 02 fe 41 15 00 00 40 00 00 02 5f 01 15 00 00 40 00 00 02 26 00 15 00 00 00 00 00 02 17 10 39 00 00 40 00 00 05 2a 00 00 04 c3 39 00 00 00 00 00 05 2b 00 00 0a 97 15 00 00 00 00 00 02 2f 02 15 00 00 40 00 00 02 35 30 39 00 00 40 00 00 03 44 00 00 39 00 00 40 00 00 03 51 00 00 15 00 00 40 00 00 02 6f 04 39 00 00 40 00 00 03 51 03 ff 15 00 00 00 00 00 02 53 20 15 00 00 40 00 00 02 90 03 39 00 00 40 00 00 13 91 ab 28 00 0c d2 00 02 4c 01 24 00 08 09 75 07 7b 10 f0 39 00 00 40 00 00 05 ff aa 55 a5 81 15 00 00 40 00 00 02 6f 0b 15 00 00 40 00 00 02 fd 80 39 00 00 40 00 00 05 ff aa 55 a5 81 15 00 00 40 00 00 02 6f 0e 15 00 00 00 00 00 02 f5 00 39 00 00 40 00 00 05 ff aa 55 a5 80 15 00 00 40 00 00 02 6f 15 39 00 00 40 00 00 03 f8 01 68 15 00 00 40 00 00 02 6f 31 39 00 00 40 00 00 03 f8 01 0e 15 00 00 40 00 00 02 6f 01 15 00 00 00 00 00 02 1f 06 39 00 00 40 00 00 05 ff aa 55 a5 80 15 00 00 40 00 00 02 6f 31 39 00 00 40 00 00 03 f8 01 0c 39 00 00 40 00 00 05 ff aa 55 a5 80 15 00 00 40 00 00 02 6f 15 39 00 00 40 00 00 03 f8 01 5f 39 00 00 40 00 00 06 f0 55 aa 52 08 01 39 00 00 00 00 00 2a c3 dd 06 22 11 ff 00 06 20 11 ff 00 04 01 11 05 95 18 04 01 11 05 95 18 04 01 11 05 95 18 04 01 11 05 95 18 04 01 11 05 95 18 39 00 00 40 00 00 06 f0 55 aa 52 08 00 39 00 00 40 00 00 02 6f 01 39 00 00 40 00 00 02 be 45 39 00 00 40 00 00 02 6f 05 39 00 00 00 00 00 02 be 88 39 00 00 40 00 00 06 f0 55 aa 52 08 00 15 00 00 40 00 00 02 b2 09 15 00 00 40 00 00 02 6f 05 39 00 00 00 00 00 03 b2 08 08 39 00 00 40 00 00 06 f0 55 aa 52 08 00 15 00 00 40 00 00 02 e2 40 15 00 00 40 00 00 02 6f 57 39 00 00 40 00 00 06 e2 ff ff ff ff ff 15 00 00 40 00 00 02 6f 37 39 00 00 00 00 00 05 e2 80 08 08 0c 39 00 00 40 00 00 06 f0 55 aa 52 08 01 15 00 00 00 00 00 02 dd 40 39 00 00 40 00 00 06 f0 55 aa 52 08 00 39 00 00 00 00 00 11 c6 ad aa aa a3 ad aa aa a3 ad aa aa a3 ad aa aa a3 39 00 00 40 00 00 05 ff aa 55 a5 80 15 00 00 40 00 00 02 6f 0a 39 00 00 40 00 00 04 f6 70 70 70 15 00 00 40 00 00 02 6f 0e 15 00 00 40 00 00 02 f6 70 15 00 00 40 00 00 02 6f 2d 15 00 00 00 00 00 02 fc 44 39 00 00 40 00 00 06 f0 55 aa 52 08 01 15 00 00 40 00 00 02 6f 01 39 00 00 40 00 00 05 d2 00 00 00 20 39 00 00 40 00 00 04 e4 80 05 5c 15 00 00 40 00 00 02 6f 07 39 00 00 40 00 00 03 e4 05 5c 15 00 00 40 00 00 02 6f 0a 39 00 00 40 00 00 04 e4 80 05 5c 15 00 00 40 00 00 02 6f 21 39 00 00 40 00 00 04 d8 60 60 60 15 00 00 40 00 00 02 6f 1e 15 00 00 40 00 00 02 d8 24 15 00 00 00 00 00 02 cd 61 39 00 00 40 00 00 06 f0 55 aa 52 08 05 39 00 00 40 00 00 03 b3 84 85 39 00 00 40 00 00 03 b5 84 85 39 00 00 40 00 00 05 b7 84 00 00 84 39 00 00 00 00 00 05 b8 84 00 00 84 39 00 00 40 00 00 06 f0 55 aa 52 08 00 15 00 00 40 00 00 02 6f 07 39 00 00 00 00 00 04 ca 08 06 58 05 00 00 00 78 00 02 11 00 05 00 00 00 00 00 02 29 00];
                    qcom,mdss-dsi-off-command = [05 00 00 00 00 00 02 28 00 05 00 00 00 64 00 02 10 00];
                    qcom,mdss-dsi-on-command-state = "dsi_lp_mode";
                    qcom,mdss-dsi-off-command-state = "dsi_lp_mode";
                    qcom,mdss-dsi-timing-switch-command = [15 00 00 00 00 00 02 2f 02 39 00 00 40 00 00 06 f0 55 aa 52 08 08 15 00 00 40 00 00 02 e0 01 39 00 00 40 00 00 05 e2 d6 4e 84 88 15 00 00 40 00 00 02 6f 12 39 00 00 40 00 00 03 e2 fd 03 39 00 00 40 00 00 09 ea 02 00 e0 00 e0 80 00 80 15 00 00 40 00 00 02 6f 17 39 00 00 00 00 00 04 ea 38 00 38];
                    qcom,mdss-dsi-timing-switch-command-update = <0x2f 0x00 0x01>;
                    qcom,mdss-dsi-timing-switch-command-state = "dsi_hs_mode";
                    qcom,mdss-dsi-nolp-command = [39 00 00 00 00 00 06 f0 55 aa 52 08 01 15 00 00 00 00 00 02 c3 dd 15 00 00 00 00 00 02 65 00 15 00 00 00 00 00 02 38 00 39 00 00 00 00 00 07 51 00 fc 00 00 03 ff 15 00 00 00 00 00 02 2c 00 39 00 00 00 00 00 06 f0 55 aa 52 08 00 39 00 00 00 00 00 02 6f 01 39 00 00 00 00 00 02 be 45];
                    qcom,mdss-dsi-nolp-command-update = <0x51 0x04 0x02>;
                    qcom,mdss-dsi-nolp-command-state = "dsi_lp_mode";
                    qcom,compression-mode = "dsc";
                    qcom,mdss-dsc-config-by-manufacture-cmd;
                    qcom,mdss-dsc-version = <0x11>;
                    qcom,mdss-dsc-scr-version = <0x01>;
                    qcom,mdss-dsc-slice-height = <0x0c>;
                    qcom,mdss-dsc-slice-width = <0x262>;
                    qcom,mdss-dsc-slice-per-pkt = <0x02>;
                    qcom,mdss-dsc-bit-per-component = <0x0a>;
                    qcom,mdss-dsc-bit-per-pixel = <0x08>;
                    qcom,mdss-dsc-block-prediction-enable;
                    mi,mdss-flat-status-control-gamma-cfg = <0x05 0x02>;
                    mi,mdss-dsi-dimmingon-command = [39 00 00 00 00 00 02 53 28];
                    mi,mdss-dsi-dimmingon-command-state = "dsi_hs_mode";
                    mi,mdss-dsi-dimmingoff-command = [39 00 00 00 00 00 02 53 20];
                    mi,mdss-dsi-dimmingoff-command-state = "dsi_hs_mode";
                    mi,mdss-dsi-hbm-fod-on-command = <0x39000000 0x551 0xfff0000>;
                    mi,mdss-dsi-hbm-fod-on-command-state = "dsi_lp_mode";
                    mi,mdss-dsi-hbm-fod-off-command = <0x39000000 0x551 0x7ff0000>;
                    mi,mdss-dsi-hbm-fod-off-command-state = "dsi_lp_mode";
                    mi,mdss-dsi-hbm-fod-off-command-update = <0x51 0x00 0x02>;
                    mi,mdss-dsi-local-hbm-normal-white-1000nit-command = [39 00 00 40 00 00 06 f0 55 aa 52 08 00 39 00 00 40 00 00 02 6f 31 39 00 00 40 00 00 02 df 22 39 00 00 40 00 00 06 f0 55 aa 52 08 02 39 00 00 40 00 00 07 d0 09 30 08 1c 0a 30 39 00 00 40 00 00 06 f0 55 aa 52 08 00 39 00 00 40 00 00 02 6f 4c 39 00 00 40 00 00 03 df 05 20 39 00 00 40 00 00 06 88 01 02 62 09 8c 39 00 00 00 00 00 04 87 25 11 11];
                    mi,mdss-dsi-local-hbm-normal-white-1000nit-command-update = <0x87 0x09 0x03 0xd0 0x04 0x06 0xdf 0x07 0x02>;
                    mi,mdss-dsi-local-hbm-normal-white-1000nit-command-state = "dsi_hs_mode";
                    mi,mdss-dsi-local-hbm-hlpm-white-1000nit-command = [15 00 00 00 00 00 02 65 00 15 00 00 00 00 00 02 38 00 39 00 00 00 00 00 07 51 00 00 00 00 03 ff 15 00 00 00 00 00 02 2c 00 39 00 00 40 00 00 06 f0 55 aa 52 08 00 39 00 00 40 00 00 02 6f 31 39 00 00 40 00 00 02 df 22 39 00 00 40 00 00 06 f0 55 aa 52 08 02 39 00 00 40 00 00 07 d0 09 30 08 1c 0a 30 39 00 00 40 00 00 06 f0 55 aa 52 08 00 39 00 00 40 00 00 02 6f 4c 39 00 00 40 00 00 03 df 05 20 39 00 00 40 00 00 06 88 01 02 62 09 8c 39 00 00 00 00 00 04 87 25 11 11];
                    mi,mdss-dsi-local-hbm-hlpm-white-1000nit-command-update = <0x87 0x0d 0x03 0xd0 0x08 0x06>;
                    mi,mdss-dsi-local-hbm-hlpm-white-1000nit-command-state = "dsi_hs_mode";
                    mi,mdss-dsi-local-hbm-normal-white-110nit-command = [39 00 00 40 00 00 06 f0 55 aa 52 08 00 39 00 00 40 00 00 02 6f 31 39 00 00 40 00 00 02 df 22 39 00 00 40 00 00 06 f0 55 aa 52 08 02 39 00 00 40 00 00 07 d0 06 55 05 cc 07 1f 39 00 00 40 00 00 06 f0 55 aa 52 08 00 39 00 00 40 00 00 02 6f 4c 39 00 00 40 00 00 03 df 05 20 39 00 00 40 00 00 06 88 01 02 62 09 8c 39 00 00 00 00 00 04 87 25 11 11];
                    mi,mdss-dsi-local-hbm-normal-white-110nit-command-update = <0x87 0x09 0x03 0xd0 0x04 0x06>;
                    mi,mdss-dsi-local-hbm-normal-white-110nit-command-state = "dsi_hs_mode";
                    mi,mdss-dsi-local-hbm-hlpm-white-110nit-command = [15 00 00 00 00 00 02 65 00 15 00 00 00 00 00 02 38 00 39 00 00 00 00 00 07 51 00 00 00 00 01 ff 15 00 00 00 00 00 02 2c 00 39 00 00 40 00 00 06 f0 55 aa 52 08 00 39 00 00 40 00 00 02 6f 31 39 00 00 40 00 00 02 df 22 39 00 00 40 00 00 06 f0 55 aa 52 08 02 39 00 00 40 00 00 07 d0 06 55 05 cc 07 1f 39 00 00 40 00 00 06 f0 55 aa 52 08 00 39 00 00 40 00 00 02 6f 4c 39 00 00 40 00 00 03 df 05 20 39 00 00 40 00 00 06 88 01 02 62 09 8c 39 00 00 00 00 00 04 87 25 11 11];
                    mi,mdss-dsi-local-hbm-hlpm-white-110nit-command-update = <0x87 0x0d 0x03 0xd0 0x08 0x06>;
                    mi,mdss-dsi-local-hbm-hlpm-white-110nit-command-state = "dsi_hs_mode";
                    mi,mdss-dsi-local-hbm-normal-green-500nit-command = [39 00 00 00 00 00 06 f0 55 aa 52 08 00 39 00 00 40 00 00 02 6f 31 39 00 00 40 00 00 02 df 22 39 00 00 40 00 00 06 f0 55 aa 52 08 02 39 00 00 40 00 00 07 d0 00 00 07 bc 00 00 39 00 00 00 00 00 06 f0 55 aa 52 08 00 39 00 00 40 00 00 02 6f 4c 39 00 00 40 00 00 03 df 05 20 39 00 00 40 00 00 06 88 01 02 62 09 8c 39 00 00 00 00 00 04 87 25 11 11];
                    mi,mdss-dsi-local-hbm-normal-green-500nit-command-update = <0x87 0x09 0x03 0xdf 0x07 0x02>;
                    mi,mdss-dsi-local-hbm-normal-green-500nit-command-state = "dsi_lp_mode";
                    mi,mdss-dsi-local-hbm-off-to-normal-command = <0x39000000 0x253 0x20390000 0x40000003 0x5107ff39 0x00 0x28700>;
                    mi,mdss-dsi-local-hbm-off-to-normal-command-update = <0x51 0x01 0x02>;
                    mi,mdss-dsi-local-hbm-off-to-normal-command-state = "dsi_hs_mode";
                    mi,mdss-dsi-local-hbm-off-to-hbm-command = [39 00 00 00 00 00 03 51 07 ff 39 00 00 00 00 00 02 87 00];
                    mi,mdss-dsi-local-hbm-off-to-hbm-command-update = <0x51 0x00 0x02>;
                    mi,mdss-dsi-local-hbm-off-to-hbm-command-state = "dsi_hs_mode";
                    mi,mdss-dsi-local-hbm-off-to-hlpm-command = <0x39000000 0x351 0x3900 0x00 0x2870039 0x4000 0x75100 0x03 0xff150000 0x40000002 0x39001500 0x400000 0x2650115 0x00 0x22c00>;
                    mi,mdss-dsi-local-hbm-off-to-hlpm-command-state = "dsi_hs_mode";
                    mi,mdss-dsi-local-hbm-off-to-llpm-command = [39 00 00 00 00 00 03 51 00 00 39 00 00 00 00 00 02 87 00 15 00 00 40 00 00 02 6f 04 39 00 00 40 00 00 03 51 01 ff 15 00 00 40 00 00 02 39 00 15 00 00 40 00 00 02 65 01 15 00 00 00 00 00 02 2c 00];
                    mi,mdss-dsi-local-hbm-off-to-llpm-command-state = "dsi_hs_mode";
                    mi,mdss-dsi-doze-hbm-command = [39 00 00 40 00 00 06 f0 55 aa 52 08 01 15 00 00 40 00 00 02 c3 00 39 00 00 40 00 00 06 f0 55 aa 52 08 00 39 00 00 40 00 00 02 6f 01 39 00 00 40 00 00 02 be 41 39 00 00 40 00 00 07 51 00 00 00 00 03 ff 15 00 00 40 00 00 02 39 00 15 00 00 40 00 00 02 65 01 15 00 00 00 00 00 02 2c 00];
                    mi,mdss-dsi-doze-hbm-command-state = "dsi_lp_mode";
                    mi,mdss-dsi-doze-lbm-command = [39 00 00 40 00 00 06 f0 55 aa 52 08 01 15 00 00 40 00 00 02 c3 00 39 00 00 40 00 00 06 f0 55 aa 52 08 00 39 00 00 40 00 00 02 6f 01 39 00 00 40 00 00 02 be 41 15 00 00 40 00 00 02 6f 04 39 00 00 40 00 00 03 51 01 ff 15 00 00 40 00 00 02 39 00 15 00 00 40 00 00 02 65 01 15 00 00 00 00 00 02 2c 00];
                    mi,mdss-dsi-doze-lbm-command-state = "dsi_lp_mode";
                    mi,mdss-dsi-doze-hbm-nolp-command = [39 00 00 00 00 00 06 f0 55 aa 52 08 01 15 00 00 00 00 00 02 c3 dd 15 00 00 00 00 00 02 65 00 15 00 00 00 00 00 02 38 00 39 00 00 00 00 00 07 51 00 fc 00 00 03 ff 15 00 00 00 00 00 02 2c 00 39 00 00 00 00 00 06 f0 55 aa 52 08 00 39 00 00 00 00 00 02 6f 01 39 00 00 00 00 00 02 be 45];
                    mi,mdss-dsi-doze-hbm-nolp-command-state = "dsi_lp_mode";
                    mi,mdss-dsi-doze-lbm-nolp-command = [39 00 00 00 00 00 06 f0 55 aa 52 08 01 15 00 00 00 00 00 02 c3 dd 15 00 00 00 00 00 02 65 00 15 00 00 00 00 00 02 38 00 39 00 00 00 00 00 07 51 00 14 00 00 01 ff 15 00 00 00 00 00 02 2c 00 39 00 00 00 00 00 06 f0 55 aa 52 08 00 39 00 00 00 00 00 02 6f 01 39 00 00 00 00 00 02 be 45];
                    mi,mdss-dsi-doze-lbm-nolp-command-state = "dsi_lp_mode";
                    mi,mdss-dsi-flat-mode-on-command = [15 00 00 00 00 00 02 5f 00 15 00 00 00 00 00 02 2f 05];
                    mi,mdss-dsi-flat-mode-on-command-state = "dsi_lp_mode";
                    mi,mdss-dsi-flat-mode-off-command = [15 00 00 00 00 00 02 5f 01 15 00 00 00 00 00 02 2f 02];
                    mi,mdss-dsi-flat-mode-off-command-state = "dsi_lp_mode";
                    mi,mdss-dsi-round-corner-on-command = [39 00 00 00 00 00 06 f0 55 aa 52 08 07 39 00 00 00 00 00 02 c0 a1];
                    mi,mdss-dsi-round-corner-on-command-state = "dsi_lp_mode";
                    mi,mdss-dsi-round-corner-off-command = [39 00 00 00 00 00 06 f0 55 aa 52 08 07 39 00 00 40 00 00 02 c0 07 39 00 00 40 00 00 02 c1 00 39 00 00 40 00 00 02 c2 00 39 00 00 40 00 00 02 c3 00 39 00 00 40 00 00 02 c4 00 39 00 00 40 00 00 02 c5 00 39 00 00 40 00 00 02 c6 00 39 00 00 40 00 00 02 c7 00 39 00 00 40 00 00 02 c8 00 39 00 00 40 00 00 02 c9 00 39 00 00 40 00 00 02 ca 00 39 00 00 40 00 00 02 cb 00 39 00 00 00 00 00 02 cc 00];
                    mi,mdss-dsi-round-corner-off-command-state = "dsi_lp_mode";
                    mi,mdss-dsi-dimming-8frame-command = <0x39000000 0x6f0 0x55aa5208 0x150000 0x02 0x6f053900 0x00 0x3b20808>;
                    mi,mdss-dsi-dimming-8frame-command-state = "dsi_lp_mode";
                    mi,mdss-dsi-dimming-4frame-command = <0x39000000 0x6f0 0x55aa5208 0x150000 0x02 0x6f053900 0x00 0x3b20404>;
                    mi,mdss-dsi-dimming-4frame-command-state = "dsi_lp_mode";
                    qcom,mdss-dsi-panel-phy-timings = [00 24 0a 0a 1a 25 09 0a 09 02 04 00 1e 0f];
                    qcom,display-topology = <0x01 0x01 0x01>;
                    qcom,default-topology-index = <0x00>;
                };
                timing@0 {
                    qcom,mdss-dsi-cmd-mode;
                    qcom,mdss-dsi-panel-framerate = <0x3c>;
                    qcom,mdss-dsi-panel-width = <0x4c4>;
                    qcom,mdss-dsi-panel-height = <0xa98>;
                    qcom,mdss-dsi-h-front-porch = <0x10>;
                    qcom,mdss-dsi-h-back-porch = <0x56>;
                    qcom,mdss-dsi-h-pulse-width = <0x10>;
                    qcom,mdss-dsi-h-sync-skew = <0x00>;
                    qcom,mdss-dsi-v-back-porch = <0x10>;
                    qcom,mdss-dsi-v-front-porch = <0x18>;
                    qcom,mdss-dsi-v-pulse-width = <0x04>;
                    qcom,mdss-dsi-h-sync-pulse = <0x00>;
                    qcom,mdss-dsi-h-left-border = <0x00>;
                    qcom,mdss-dsi-h-right-border = <0x00>;
                    qcom,mdss-dsi-v-top-border = <0x00>;
                    qcom,mdss-dsi-v-bottom-border = <0x00>;
                    qcom,mdss-dsi-panel-clockrate = <0x4190ab00>;
                    qcom,mdss-dsi-panel-jitter = <0x05 0x01>;
                    qcom,mdss-mdp-transfer-time-us = <0x1c84>;
                    qcom,mdss-dsi-on-command = [39 00 00 00 00 00 06 f0 55 aa 52 08 08 39 00 00 40 00 00 06 e0 41 73 73 73 83 39 00 00 40 00 00 16 e1 00 00 00 00 00 00 00 00 00 00 00 00 00 00 00 00 00 00 00 00 00 39 00 00 40 00 00 16 e2 80 ef 66 86 00 00 00 00 00 00 00 00 00 00 00 00 00 00 02 01 00 39 00 00 40 00 00 16 e3 00 00 00 00 00 00 00 00 00 00 00 00 00 00 00 00 00 00 00 00 00 39 00 00 40 00 00 13 e4 00 00 00 00 00 00 00 00 00 00 00 00 00 00 00 00 00 00 39 00 00 40 00 00 13 e5 00 00 00 00 00 00 00 00 00 00 00 00 00 00 00 00 00 00 39 00 00 00 00 00 13 e6 00 00 00 00 00 00 00 00 00 00 00 00 00 00 00 00 00 00 39 00 00 40 00 00 06 f0 55 aa 52 08 07 15 00 00 40 00 00 02 6f 37 39 00 00 40 00 00 04 b7 08 08 08 39 00 00 40 00 00 06 f0 55 aa 52 08 00 15 00 00 40 00 00 02 6f 37 39 00 00 40 00 00 04 b7 08 08 08 39 00 00 40 00 00 06 f0 55 aa 52 08 00 15 00 00 40 00 00 02 6f 01 15 00 00 40 00 00 02 c0 20 39 00 00 40 00 00 06 f0 55 aa 52 08 08 39 00 00 40 00 00 22 ea 02 00 e0 00 e0 70 00 70 00 00 00 00 00 00 00 00 00 00 00 00 00 00 00 00 00 00 00 00 00 00 00 00 00 15 00 00 40 00 00 02 6f 15 39 00 00 40 00 00 07 ea 00 00 80 00 80 00 39 00 00 40 00 00 06 f0 55 aa 52 08 08 15 00 00 40 00 00 02 6f 21 39 00 00 00 00 00 07 ea 00 00 00 00 00 00 39 00 00 40 00 00 06 f0 55 aa 52 08 08 15 00 00 40 00 00 02 e0 01 39 00 00 40 00 00 05 e2 88 e0 cc 0c 15 00 00 40 00 00 02 6f 12 39 00 00 40 00 00 03 e2 86 01 39 00 00 40 00 00 09 ea 02 00 e0 00 e0 70 00 70 15 00 00 40 00 00 02 6f 17 39 00 00 00 00 00 04 ea 80 00 80 39 00 00 40 00 00 06 f0 55 aa 52 08 00 15 00 00 40 00 00 02 6f 13 15 00 00 00 00 00 02 b2 4f 39 00 00 40 00 00 05 ff aa 55 a5 81 15 00 00 40 00 00 02 6f 19 15 00 00 40 00 00 02 fb 00 15 00 00 40 00 00 02 6f 05 15 00 00 00 00 00 02 fe 34 39 00 00 40 00 00 05 ff aa 55 a5 80 15 00 00 40 00 00 02 6f 1a 15 00 00 40 00 00 02 f4 55 15 00 00 40 00 00 02 6f 0f 15 00 00 40 00 00 02 fc 00 15 00 00 40 00 00 02 6f 09 39 00 00 00 00 00 03 fc fc f0 39 00 00 40 00 00 05 ff aa 55 a5 83 15 00 00 40 00 00 02 6f 12 15 00 00 00 00 00 02 fe 41 15 00 00 40 00 00 02 5f 01 15 00 00 40 00 00 02 26 00 15 00 00 00 00 00 02 17 10 39 00 00 40 00 00 05 2a 00 00 04 c3 39 00 00 00 00 00 05 2b 00 00 0a 97 15 00 00 00 00 00 02 2f 00 15 00 00 40 00 00 02 35 30 39 00 00 40 00 00 03 44 00 00 39 00 00 40 00 00 03 51 00 00 15 00 00 40 00 00 02 6f 04 39 00 00 40 00 00 03 51 03 ff 15 00 00 00 00 00 02 53 20 15 00 00 40 00 00 02 90 03 39 00 00 40 00 00 13 91 ab 28 00 0c d2 00 02 4c 01 24 00 08 09 75 07 7b 10 f0 39 00 00 40 00 00 05 ff aa 55 a5 81 15 00 00 40 00 00 02 6f 0b 15 00 00 40 00 00 02 fd 80 39 00 00 40 00 00 05 ff aa 55 a5 81 15 00 00 40 00 00 02 6f 0e 15 00 00 00 00 00 02 f5 00 39 00 00 40 00 00 05 ff aa 55 a5 80 15 00 00 40 00 00 02 6f 15 39 00 00 40 00 00 03 f8 01 68 15 00 00 40 00 00 02 6f 31 39 00 00 40 00 00 03 f8 01 0e 15 00 00 40 00 00 02 6f 01 15 00 00 00 00 00 02 1f 06 39 00 00 40 00 00 05 ff aa 55 a5 80 15 00 00 40 00 00 02 6f 31 39 00 00 40 00 00 03 f8 01 0c 39 00 00 40 00 00 05 ff aa 55 a5 80 15 00 00 40 00 00 02 6f 15 39 00 00 40 00 00 03 f8 01 5f 39 00 00 40 00 00 06 f0 55 aa 52 08 01 39 00 00 00 00 00 2a c3 dd 06 22 11 ff 00 06 20 11 ff 00 04 01 11 05 95 18 04 01 11 05 95 18 04 01 11 05 95 18 04 01 11 05 95 18 04 01 11 05 95 18 39 00 00 40 00 00 06 f0 55 aa 52 08 00 39 00 00 40 00 00 02 6f 01 39 00 00 40 00 00 02 be 45 39 00 00 40 00 00 02 6f 05 39 00 00 00 00 00 02 be 88 39 01 00 40 00 00 06 f0 55 aa 52 08 00 15 01 00 40 00 00 02 b2 09 15 01 00 40 00 00 02 6f 05 39 01 00 00 00 00 03 b2 08 08 39 00 00 40 00 00 06 f0 55 aa 52 08 00 15 00 00 40 00 00 02 e2 40 15 00 00 40 00 00 02 6f 57 39 00 00 40 00 00 06 e2 ff ff ff ff ff 15 00 00 40 00 00 02 6f 37 39 00 00 00 00 00 05 e2 80 08 08 0c 39 00 00 40 00 00 06 f0 55 aa 52 08 01 15 00 00 00 00 00 02 dd 40 39 00 00 40 00 00 06 f0 55 aa 52 08 00 39 00 00 00 00 00 11 c6 ad aa aa a3 ad aa aa a3 ad aa aa a3 ad aa aa a3 39 00 00 40 00 00 05 ff aa 55 a5 80 15 00 00 40 00 00 02 6f 0a 39 00 00 40 00 00 04 f6 70 70 70 15 00 00 40 00 00 02 6f 0e 15 00 00 40 00 00 02 f6 70 15 00 00 40 00 00 02 6f 2d 15 00 00 00 00 00 02 fc 44 39 00 00 40 00 00 06 f0 55 aa 52 08 01 15 00 00 40 00 00 02 6f 01 39 00 00 40 00 00 05 d2 00 00 00 20 39 00 00 40 00 00 04 e4 80 05 5c 15 00 00 40 00 00 02 6f 07 39 00 00 40 00 00 03 e4 05 5c 15 00 00 40 00 00 02 6f 0a 39 00 00 40 00 00 04 e4 80 05 5c 15 00 00 40 00 00 02 6f 21 39 00 00 40 00 00 04 d8 60 60 60 15 00 00 40 00 00 02 6f 1e 15 00 00 40 00 00 02 d8 24 15 00 00 00 00 00 02 cd 61 39 00 00 40 00 00 06 f0 55 aa 52 08 05 39 00 00 40 00 00 03 b3 84 85 39 00 00 40 00 00 03 b5 84 85 39 00 00 40 00 00 05 b7 84 00 00 84 39 00 00 00 00 00 05 b8 84 00 00 84 39 00 00 40 00 00 06 f0 55 aa 52 08 00 15 00 00 40 00 00 02 6f 07 39 00 00 00 00 00 04 ca 08 06 58 05 00 00 00 78 00 02 11 00 05 00 00 00 00 00 02 29 00];
                    qcom,mdss-dsi-off-command = [05 00 00 00 00 00 02 28 00 05 00 00 00 64 00 02 10 00];
                    qcom,mdss-dsi-on-command-state = "dsi_lp_mode";
                    qcom,mdss-dsi-off-command-state = "dsi_lp_mode";
                    qcom,mdss-dsi-timing-switch-command = [15 00 00 00 00 00 02 2f 00 39 00 00 40 00 00 06 f0 55 aa 52 08 08 15 00 00 40 00 00 02 e0 01 39 00 00 40 00 00 05 e2 88 e0 cc 0c 15 00 00 40 00 00 02 6f 12 39 00 00 40 00 00 03 e2 86 01 39 00 00 40 00 00 09 ea 02 00 e0 00 e0 70 00 70 15 00 00 40 00 00 02 6f 17 39 00 00 00 00 00 04 ea 80 00 80];
                    qcom,mdss-dsi-timing-switch-command-update = <0x2f 0x00 0x01>;
                    qcom,mdss-dsi-timing-switch-command-state = "dsi_hs_mode";
                    qcom,mdss-dsi-nolp-command = [39 00 00 00 00 00 06 f0 55 aa 52 08 01 15 00 00 00 00 00 02 c3 dd 15 00 00 00 00 00 02 65 00 15 00 00 00 00 00 02 38 00 39 00 00 00 00 00 07 51 00 fc 00 00 03 ff 15 00 00 00 00 00 02 2c 00 39 00 00 00 00 00 06 f0 55 aa 52 08 00 39 00 00 00 00 00 02 6f 01 39 00 00 00 00 00 02 be 45];
                    qcom,mdss-dsi-nolp-command-update = <0x51 0x04 0x02>;
                    qcom,mdss-dsi-nolp-command-state = "dsi_lp_mode";
                    qcom,compression-mode = "dsc";
                    qcom,mdss-dsc-config-by-manufacture-cmd;
                    qcom,mdss-dsc-version = <0x11>;
                    qcom,mdss-dsc-scr-version = <0x01>;
                    qcom,mdss-dsc-slice-height = <0x0c>;
                    qcom,mdss-dsc-slice-width = <0x262>;
                    qcom,mdss-dsc-slice-per-pkt = <0x02>;
                    qcom,mdss-dsc-bit-per-component = <0x0a>;
                    qcom,mdss-dsc-bit-per-pixel = <0x08>;
                    qcom,mdss-dsc-block-prediction-enable;
                    mi,mdss-flat-status-control-gamma-cfg = <0x03 0x00>;
                    mi,mdss-dsi-dimmingon-command = [39 00 00 00 00 00 02 53 28];
                    mi,mdss-dsi-dimmingon-command-state = "dsi_hs_mode";
                    mi,mdss-dsi-dimmingoff-command = [39 00 00 00 00 00 02 53 20];
                    mi,mdss-dsi-dimmingoff-command-state = "dsi_hs_mode";
                    mi,mdss-dsi-hbm-fod-on-command = <0x39000000 0x551 0xfff0000>;
                    mi,mdss-dsi-hbm-fod-on-command-state = "dsi_lp_mode";
                    mi,mdss-dsi-hbm-fod-off-command = <0x39000000 0x551 0x7ff0000>;
                    mi,mdss-dsi-hbm-fod-off-command-state = "dsi_lp_mode";
                    mi,mdss-dsi-hbm-fod-off-command-update = <0x51 0x00 0x02>;
                    mi,mdss-dsi-local-hbm-normal-white-1000nit-command = [39 00 00 40 00 00 06 f0 55 aa 52 08 00 39 00 00 40 00 00 02 6f 31 39 00 00 40 00 00 02 df 22 39 00 00 40 00 00 06 f0 55 aa 52 08 02 39 00 00 40 00 00 07 d0 09 30 08 1c 0a 30 39 00 00 40 00 00 06 f0 55 aa 52 08 00 39 00 00 40 00 00 02 6f 4c 39 00 00 40 00 00 03 df 05 20 39 00 00 40 00 00 06 88 01 02 62 09 8c 39 00 00 00 00 00 04 87 25 11 11];
                    mi,mdss-dsi-local-hbm-normal-white-1000nit-command-update = <0x87 0x09 0x03 0xd0 0x04 0x06 0xdf 0x07 0x02>;
                    mi,mdss-dsi-local-hbm-normal-white-1000nit-command-state = "dsi_hs_mode";
                    mi,mdss-dsi-local-hbm-hlpm-white-1000nit-command = [15 00 00 00 00 00 02 65 00 15 00 00 00 00 00 02 38 00 39 00 00 00 00 00 07 51 00 00 00 00 03 ff 15 00 00 00 00 00 02 2c 00 39 00 00 40 00 00 06 f0 55 aa 52 08 00 39 00 00 40 00 00 02 6f 31 39 00 00 40 00 00 02 df 22 39 00 00 40 00 00 06 f0 55 aa 52 08 02 39 00 00 40 00 00 07 d0 09 30 08 1c 0a 30 39 00 00 40 00 00 06 f0 55 aa 52 08 00 39 00 00 40 00 00 02 6f 4c 39 00 00 40 00 00 03 df 05 20 39 00 00 40 00 00 06 88 01 02 62 09 8c 39 00 00 00 00 00 04 87 25 11 11];
                    mi,mdss-dsi-local-hbm-hlpm-white-1000nit-command-update = <0x87 0x0d 0x03 0xd0 0x08 0x06>;
                    mi,mdss-dsi-local-hbm-hlpm-white-1000nit-command-state = "dsi_hs_mode";
                    mi,mdss-dsi-local-hbm-normal-white-110nit-command = [39 00 00 40 00 00 06 f0 55 aa 52 08 00 39 00 00 40 00 00 02 6f 31 39 00 00 40 00 00 02 df 22 39 00 00 40 00 00 06 f0 55 aa 52 08 02 39 00 00 40 00 00 07 d0 06 55 05 cc 07 1f 39 00 00 40 00 00 06 f0 55 aa 52 08 00 39 00 00 40 00 00 02 6f 4c 39 00 00 40 00 00 03 df 05 20 39 00 00 40 00 00 06 88 01 02 62 09 8c 39 00 00 00 00 00 04 87 25 11 11];
                    mi,mdss-dsi-local-hbm-normal-white-110nit-command-update = <0x87 0x09 0x03 0xd0 0x04 0x06>;
                    mi,mdss-dsi-local-hbm-normal-white-110nit-command-state = "dsi_hs_mode";
                    mi,mdss-dsi-local-hbm-hlpm-white-110nit-command = [15 00 00 00 00 00 02 65 00 15 00 00 00 00 00 02 38 00 39 00 00 00 00 00 07 51 00 00 00 00 01 ff 15 00 00 00 00 00 02 2c 00 39 00 00 40 00 00 06 f0 55 aa 52 08 00 39 00 00 40 00 00 02 6f 31 39 00 00 40 00 00 02 df 22 39 00 00 40 00 00 06 f0 55 aa 52 08 02 39 00 00 40 00 00 07 d0 06 55 05 cc 07 1f 39 00 00 40 00 00 06 f0 55 aa 52 08 00 39 00 00 40 00 00 02 6f 4c 39 00 00 40 00 00 03 df 05 20 39 00 00 40 00 00 06 88 01 02 62 09 8c 39 00 00 00 00 00 04 87 25 11 11];
                    mi,mdss-dsi-local-hbm-hlpm-white-110nit-command-update = <0x87 0x0d 0x03 0xd0 0x08 0x06>;
                    mi,mdss-dsi-local-hbm-hlpm-white-110nit-command-state = "dsi_hs_mode";
                    mi,mdss-dsi-local-hbm-normal-green-500nit-command = [39 00 00 00 00 00 06 f0 55 aa 52 08 00 39 00 00 40 00 00 02 6f 31 39 00 00 40 00 00 02 df 22 39 00 00 40 00 00 06 f0 55 aa 52 08 02 39 00 00 40 00 00 07 d0 00 00 07 bc 00 00 39 00 00 00 00 00 06 f0 55 aa 52 08 00 39 00 00 40 00 00 02 6f 4c 39 00 00 40 00 00 03 df 05 20 39 00 00 40 00 00 06 88 01 02 62 09 8c 39 00 00 00 00 00 04 87 25 11 11];
                    mi,mdss-dsi-local-hbm-normal-green-500nit-command-update = <0x87 0x09 0x03 0xdf 0x07 0x02>;
                    mi,mdss-dsi-local-hbm-normal-green-500nit-command-state = "dsi_lp_mode";
                    mi,mdss-dsi-local-hbm-off-to-normal-command = <0x39000000 0x253 0x20390000 0x40000003 0x5107ff39 0x00 0x28700>;
                    mi,mdss-dsi-local-hbm-off-to-normal-command-update = <0x51 0x01 0x02>;
                    mi,mdss-dsi-local-hbm-off-to-normal-command-state = "dsi_hs_mode";
                    mi,mdss-dsi-local-hbm-off-to-hbm-command = [39 00 00 00 00 00 03 51 07 ff 39 00 00 00 00 00 02 87 00];
                    mi,mdss-dsi-local-hbm-off-to-hbm-command-update = <0x51 0x00 0x02>;
                    mi,mdss-dsi-local-hbm-off-to-hbm-command-state = "dsi_hs_mode";
                    mi,mdss-dsi-local-hbm-off-to-hlpm-command = <0x39000000 0x351 0x3900 0x00 0x2870039 0x4000 0x75100 0x03 0xff150000 0x40000002 0x39001500 0x400000 0x2650115 0x00 0x22c00>;
                    mi,mdss-dsi-local-hbm-off-to-hlpm-command-state = "dsi_hs_mode";
                    mi,mdss-dsi-local-hbm-off-to-llpm-command = [39 00 00 00 00 00 03 51 00 00 39 00 00 00 00 00 02 87 00 15 00 00 40 00 00 02 6f 04 39 00 00 40 00 00 03 51 01 ff 15 00 00 40 00 00 02 39 00 15 00 00 40 00 00 02 65 01 15 00 00 00 00 00 02 2c 00];
                    mi,mdss-dsi-local-hbm-off-to-llpm-command-state = "dsi_hs_mode";
                    mi,mdss-dsi-doze-hbm-command = [39 00 00 40 00 00 06 f0 55 aa 52 08 01 15 00 00 40 00 00 02 c3 00 39 00 00 40 00 00 06 f0 55 aa 52 08 00 39 00 00 40 00 00 02 6f 01 39 00 00 40 00 00 02 be 41 39 00 00 40 00 00 07 51 00 00 00 00 03 ff 15 00 00 40 00 00 02 39 00 15 00 00 40 00 00 02 65 01 15 00 00 00 00 00 02 2c 00];
                    mi,mdss-dsi-doze-hbm-command-state = "dsi_lp_mode";
                    mi,mdss-dsi-doze-lbm-command = [39 00 00 40 00 00 06 f0 55 aa 52 08 01 15 00 00 40 00 00 02 c3 00 39 00 00 40 00 00 06 f0 55 aa 52 08 00 39 00 00 40 00 00 02 6f 01 39 00 00 40 00 00 02 be 41 15 00 00 40 00 00 02 6f 04 39 00 00 40 00 00 03 51 01 ff 15 00 00 40 00 00 02 39 00 15 00 00 40 00 00 02 65 01 15 00 00 00 00 00 02 2c 00];
                    mi,mdss-dsi-doze-lbm-command-state = "dsi_lp_mode";
                    mi,mdss-dsi-doze-hbm-nolp-command = [39 00 00 00 00 00 06 f0 55 aa 52 08 01 15 00 00 00 00 00 02 c3 dd 15 00 00 00 00 00 02 65 00 15 00 00 00 00 00 02 38 00 39 00 00 00 00 00 07 51 00 fc 00 00 03 ff 15 00 00 00 00 00 02 2c 00 39 00 00 00 00 00 06 f0 55 aa 52 08 00 39 00 00 00 00 00 02 6f 01 39 00 00 00 00 00 02 be 45];
                    mi,mdss-dsi-doze-hbm-nolp-command-state = "dsi_lp_mode";
                    mi,mdss-dsi-doze-lbm-nolp-command = [39 00 00 00 00 00 06 f0 55 aa 52 08 01 15 00 00 00 00 00 02 c3 dd 15 00 00 00 00 00 02 65 00 15 00 00 00 00 00 02 38 00 39 00 00 00 00 00 07 51 00 14 00 00 01 ff 15 00 00 00 00 00 02 2c 00 39 00 00 00 00 00 06 f0 55 aa 52 08 00 39 00 00 00 00 00 02 6f 01 39 00 00 00 00 00 02 be 45];
                    mi,mdss-dsi-doze-lbm-nolp-command-state = "dsi_lp_mode";
                    mi,mdss-dsi-flat-mode-on-command = [15 00 00 00 00 00 02 5f 00 15 00 00 00 00 00 02 2f 03];
                    mi,mdss-dsi-flat-mode-on-command-state = "dsi_lp_mode";
                    mi,mdss-dsi-flat-mode-off-command = [15 00 00 00 00 00 02 5f 01 15 00 00 00 00 00 02 2f 00];
                    mi,mdss-dsi-flat-mode-off-command-state = "dsi_lp_mode";
                    mi,mdss-dsi-round-corner-on-command = [39 00 00 00 00 00 06 f0 55 aa 52 08 07 39 00 00 00 00 00 02 c0 a1];
                    mi,mdss-dsi-round-corner-on-command-state = "dsi_lp_mode";
                    mi,mdss-dsi-round-corner-off-command = [39 00 00 00 00 00 06 f0 55 aa 52 08 07 39 00 00 40 00 00 02 c0 07 39 00 00 40 00 00 02 c1 00 39 00 00 40 00 00 02 c2 00 39 00 00 40 00 00 02 c3 00 39 00 00 40 00 00 02 c4 00 39 00 00 40 00 00 02 c5 00 39 00 00 40 00 00 02 c6 00 39 00 00 40 00 00 02 c7 00 39 00 00 40 00 00 02 c8 00 39 00 00 40 00 00 02 c9 00 39 00 00 40 00 00 02 ca 00 39 00 00 40 00 00 02 cb 00 39 00 00 00 00 00 02 cc 00];
                    mi,mdss-dsi-round-corner-off-command-state = "dsi_lp_mode";
                    mi,mdss-dsi-dimming-8frame-command = <0x39000000 0x6f0 0x55aa5208 0x150000 0x02 0x6f053900 0x00 0x3b20808>;
                    mi,mdss-dsi-dimming-8frame-command-state = "dsi_lp_mode";
                    mi,mdss-dsi-dimming-4frame-command = <0x39000000 0x6f0 0x55aa5208 0x150000 0x02 0x6f053900 0x00 0x3b20404>;
                    mi,mdss-dsi-dimming-4frame-command-state = "dsi_lp_mode";
                    qcom,mdss-dsi-panel-phy-timings = [00 24 0a 0a 1a 25 09 0a 09 02 04 00 1e 0f];
                    qcom,display-topology = <0x01 0x01 0x01>;
                    qcom,default-topology-index = <0x00>;
                };
            };
        };

        qcom,mdss_dsi_l12_42_02_0a_dsc_cmd {
            qcom,mdss-dsi-panel-name = "xiaomi 42 02 0a mp cmd mode dsc dsi panel";
            qcom,mdss-dsi-panel-type = "dsi_cmd_mode";
            qcom,mdss-dsi-virtual-channel-id = <0x00>;
            qcom,mdss-dsi-stream = <0x00>;
            qcom,mdss-dsi-bpp = <0x1e>;
            qcom,mdss-dsi-color-order = "rgb_swap_rgb";
            qcom,mdss-dsi-underflow-color = <0xff>;
            qcom,mdss-dsi-border-color = <0x00>;
            qcom,dsi-ctrl-num = <0x00>;
            qcom,dsi-phy-num = <0x00>;
            qcom,mdss-dsi-traffic-mode = "burst_mode";
            qcom,mdss-dsi-lane-map = "lane_map_0123";
            qcom,mdss-dsi-bllp-eof-power-mode;
            qcom,mdss-dsi-bllp-power-mode;
            qcom,mdss-dsi-lane-0-state;
            qcom,mdss-dsi-lane-1-state;
            qcom,mdss-dsi-lane-2-state;
            qcom,mdss-dsi-lane-3-state;
            qcom,mdss-dsi-dma-trigger = "trigger_sw";
            qcom,mdss-dsi-mdp-trigger = "none";
            qcom,mdss-dsi-reset-sequence = <0x01 0x0b 0x00 0x01 0x01 0x0b>;
            qcom,mdss-pan-physical-width-dimension = <0x2b7>;
            qcom,mdss-pan-physical-height-dimension = <0x609>;
            qcom,mdss-dsi-te-pin-select = <0x01>;
            qcom,mdss-dsi-wr-mem-start = <0x2c>;
            qcom,mdss-dsi-wr-mem-continue = <0x3c>;
            qcom,mdss-dsi-te-dcs-command = <0x01>;
            qcom,mdss-dsi-te-check-enable;
            qcom,mdss-dsi-te-using-te-pin;
            qcom,mdss-dsi-tx-eot-append;
            qcom,mdss-dsi-lp11-init;
            qcom,mdss-dsi-bl-inverted-dbv;
            qcom,bl-update-flag = "delay_until_first_frame";
            qcom,mdss-dsi-panel-mode-switch;
            qcom,mdss-dsi-panel-hdr-enabled;
            qcom,mdss-dsi-panel-hdr-color-primaries = <0x38a4 0x3c8c 0x7d00 0x4268 0x3c8c 0x7530 0x1f40 0xbb8>;
            qcom,mdss-dsi-panel-peak-brightness = <0x401640>;
            qcom,mdss-dsi-panel-blackness-level = <0xc9e>;
            qcom,mdss-dsi-dma-schedule-line = <0x01>;
            qcom,mdss-dsi-dma-schedule-window = <0x0a>;
            mi,panel-id = <0x4c3132 0x420200>;
            mi,esd-err-irq-gpio = <&tlmm 0x74 0x2008>;
            mi,local-hbm-enabled;
            mi,local-hbm-white-1000nit-update-flag;
            mi,local-hbm-white-110nit-update-flag;
            mi,local-hbm-alpha-ctrl-aa-area;
            mi,panel-on-dimming-delay = <0x78>;
            mi,max-brightness-clone = <0xfff>;
            mi,normal-max-brightness-clone = <0x7ff>;
            mi,mdss-dsi-fac-bl-max-level = <0x7ff>;
            mi,mdss-fac-brightness-max-level = <0x7ff>;
            mi,hbm-bl-min-level = <0x01>;
            mi,hbm-bl-max-level = <0x7ff>;
            mi,doze-hbm-dbv-level = <0xfc>;
            mi,doze-lbm-dbv-level = <0x14>;
            mi,thermal-dimming-flag;
            mi,ddic-round-corner-enabled;
            mi,fod-low-brightness-clone-threshold = <0xc8>;
            mi,fod-low-brightness-lux-threshold = <0x03>;
            mi,flat-update-flag;
            mi,flat-need-sync-te;
            mi,flat-need-update-gamma-zero;
            mi,local-hbm-ui-ready-delay-num-frame = <0x04>;
            qcom,mdss-dsi-bl-pmic-control-type = "bl_ctrl_dcs";
            qcom,mdss-dsi-bl-min-level = <0x01>;
            qcom,mdss-dsi-bl-max-level = <0xfff>;
            qcom,mdss-brightness-max-level = <0xfff>;
            qcom,platform-reset-gpio = <&tlmm 0x00 0x00>;
            qcom,ulps-enabled;
            qcom,dsi-select-clocks = "pll_byte_clk0", "pll_dsi_clk0";
            qcom,mdss-dsi-display-timings {
                timing@2 {
                    qcom,mdss-dsi-cmd-mode;
                    qcom,mdss-dsi-panel-framerate = <0x5a>;
                    qcom,mdss-dsi-panel-width = <0x4c4>;
                    qcom,mdss-dsi-panel-height = <0xa98>;
                    qcom,mdss-dsi-h-front-porch = <0x10>;
                    qcom,mdss-dsi-h-back-porch = <0x56>;
                    qcom,mdss-dsi-h-pulse-width = <0x10>;
                    qcom,mdss-dsi-h-sync-skew = <0x00>;
                    qcom,mdss-dsi-v-back-porch = <0x14>;
                    qcom,mdss-dsi-v-front-porch = <0x14>;
                    qcom,mdss-dsi-v-pulse-width = <0x04>;
                    qcom,mdss-dsi-h-sync-pulse = <0x00>;
                    qcom,mdss-dsi-h-left-border = <0x00>;
                    qcom,mdss-dsi-h-right-border = <0x00>;
                    qcom,mdss-dsi-v-top-border = <0x00>;
                    qcom,mdss-dsi-v-bottom-border = <0x00>;
                    qcom,mdss-dsi-panel-clockrate = <0x4190ab00>;
                    qcom,mdss-dsi-panel-jitter = <0x05 0x01>;
                    qcom,mdss-mdp-transfer-time-us = <0x1c84>;
                    qcom,mdss-dsi-on-command = <0x39000000 0x6f0 0x55aa5208 0x150000 0x40000002 0x6f061500 0x400000 0x2b52c15 0x4000 0x26f0c 0x15000000 0x2b5 0x2c390000 0x40000006 0xf055aa52 0x8033900 0x00 0x1eb00f00 0xf0002 0xf00000f 0xf00 0xf0000 0xf00000f 0xf00 0xf0039 0x4000 0x6f055 0xaa520805 0x39000040 0x4d0 0x71039 0x4000 0x5e000 0xa9e0239 0x4000 0x6f055 0xaa520806 0x39000040 0x6b1 0x32310f32 0x31150000 0x40000002 0xb30e3900 0x400000 0x6b73231 0xf323115 0x00 0x2b90e 0x39000040 0x5ff 0xaa55a580 0x15000040 0x26f 0x1d150000 0x40000002 0xf2053900 0x400000 0x6f055aa 0x52080015 0x4000 0x26f1c 0x39000040 0x4c0 0x3121139 0x4000 0x6f055 0xaa520800 0x15000000 0x203 0x1390000 0x05 0x3b001400 0x14150000 0x02 0x90113900 0x400000 0x1391ab28 0xcc200 0x2320131 0x808bb 0x77b10f0 0x15000000 0x22c 0x390000 0x40000005 0x5100000f 0xfe150000 0x02 0x53201500 0x00 0x2350039 0x4000 0x52a00 0x4c339 0x4000 0x52b00 0xa9715 0x4000 0x22f04 0x15000040 0x25f 0x1390000 0x40000006 0xf055aa52 0x8001500 0x400000 0x26f0b15 0x4000 0x2c020 0x39000040 0x6f0 0x55aa5208 0x2150000 0x40000002 0xcc301500 0x1400 0x2ce0115 0x00 0x2cc00 0x39000040 0x6f0 0x55aa5208 0x1390000 0x08 0xc39b0194 0xd0220200 0x39000040 0x6f0 0x55aa5208 0x7390000 0x02 0xc0013900 0x400000 0x6f055aa 0x52080039 0x4000 0x26f05 0x39000000 0x2be 0x88390000 0x40000006 0xf055aa52 0x8001500 0x400000 0x26f0215 0x00 0x2c1d8 0x39000040 0x5ff 0xaa55a580 0x15000040 0x26f 0x61150000 0x02 0xf3803900 0x400000 0x6f055aa 0x52080415 0x4000 0x26f0d 0x15000000 0x2ca 0x5390100 0x40000006 0xf055aa52 0x8001501 0x400000 0x2b29815 0x1004000 0x26f02 0x39010000 0x3b2 0xa0a0500 0x7800 0x2110005 0x00 0x22900>;
                    qcom,mdss-dsi-off-command = [05 00 00 00 14 00 02 28 00 05 00 00 00 64 00 02 10 00];
                    qcom,mdss-dsi-on-command-state = "dsi_lp_mode";
                    qcom,mdss-dsi-off-command-state = "dsi_lp_mode";
                    qcom,mdss-dsi-nolp-command = [39 00 00 00 00 00 06 f0 55 aa 52 08 00 39 00 00 00 00 00 02 b2 98 39 00 00 40 00 00 02 65 00 39 00 00 40 00 00 01 38 39 00 00 40 00 00 05 51 00 fc 0f fe 39 00 00 00 00 00 01 2c];
                    qcom,mdss-dsi-nolp-command-update = <0x51 0x04 0x02>;
                    qcom,mdss-dsi-nolp-command-state = "dsi_lp_mode";
                    qcom,mdss-dsi-timing-switch-command = <0x15000000 0x22f 0x4390000 0x40000006 0xf055aa52 0x8001500 0x400000 0x26f0b15 0x4000 0x2c020 0x39000040 0x6f0 0x55aa5208 0x2150000 0x40000002 0xcc301500 0xd00 0x2ce0115 0x00 0x2cc00>;
                    qcom,mdss-dsi-timing-switch-command-update = <0xc0 0x03 0x01>;
                    qcom,mdss-dsi-timing-switch-command-state = "dsi_hs_mode";
                    qcom,compression-mode = "dsc";
                    qcom,mdss-dsc-config-by-manufacture-cmd;
                    qcom,mdss-dsc-version = <0x11>;
                    qcom,mdss-dsc-scr-version = <0x00>;
                    qcom,mdss-dsc-slice-height = <0x0c>;
                    qcom,mdss-dsc-slice-width = <0x262>;
                    qcom,mdss-dsc-slice-per-pkt = <0x02>;
                    qcom,mdss-dsc-bit-per-component = <0x0a>;
                    qcom,mdss-dsc-bit-per-pixel = <0x08>;
                    qcom,mdss-dsc-block-prediction-enable;
                    mi,mdss-flat-status-control-gamma-cfg = <0x60 0x20>;
                    mi,mdss-dsi-dimmingon-command = [39 00 00 00 00 00 02 53 28];
                    mi,mdss-dsi-dimmingon-command-state = "dsi_hs_mode";
                    mi,mdss-dsi-dimmingoff-command = [39 00 00 00 00 00 02 53 20];
                    mi,mdss-dsi-dimmingoff-command-state = "dsi_hs_mode";
                    mi,mdss-dsi-hbm-fod-on-command = [39 00 00 00 00 00 03 51 0f ff];
                    mi,mdss-dsi-hbm-fod-on-command-state = "dsi_lp_mode";
                    mi,mdss-dsi-hbm-fod-off-command = [39 00 00 00 00 00 03 51 07 ff];
                    mi,mdss-dsi-hbm-fod-off-command-state = "dsi_lp_mode";
                    mi,mdss-dsi-hbm-fod-off-command-update = <0x51 0x00 0x02>;
                    mi,mdss-dsi-local-hbm-normal-white-1000nit-command = [39 00 00 40 00 00 06 f0 55 aa 52 08 00 39 00 00 40 00 00 02 6f 17 39 00 00 40 00 00 03 b2 07 ff 39 00 00 40 00 00 02 6f 1f 39 00 00 40 00 00 03 b2 00 50 39 00 00 40 00 00 06 f0 55 aa 52 08 02 39 00 00 40 00 00 02 d1 01 39 00 00 40 00 00 02 6f 08 39 00 00 40 00 00 07 d0 09 6a 08 3d 0a 18 39 00 00 40 00 00 06 f0 55 aa 52 08 07 39 00 00 40 00 00 02 d9 40 39 00 00 40 00 00 02 c0 01 39 00 00 40 00 00 03 51 07 ff 39 00 00 40 00 00 02 6f 01 39 00 00 40 00 00 05 88 02 62 09 8c 39 00 00 40 00 00 03 87 11 11 39 00 00 40 00 00 02 88 01 39 00 00 00 00 00 02 85 01];
                    mi,mdss-dsi-local-hbm-normal-white-1000nit-command-update = <0x87 0x0f 0x02 0x51 0x0c 0x02 0xd0 0x08 0x06>;
                    mi,mdss-dsi-local-hbm-normal-white-1000nit-command-state = "dsi_hs_mode";
                    mi,mdss-dsi-local-hbm-hlpm-white-1000nit-command = [39 00 00 00 00 00 06 f0 55 aa 52 08 00 39 00 00 00 00 00 02 b2 98 39 00 00 00 00 00 02 65 00 39 00 00 00 32 00 02 38 00 39 00 00 00 00 00 02 2c 00 39 00 00 00 00 00 06 f0 55 aa 52 08 00 39 00 00 40 00 00 02 6f 17 39 00 00 40 00 00 03 b2 07 ff 39 00 00 40 00 00 02 6f 1f 39 00 00 40 00 00 03 b2 00 50 39 00 00 40 00 00 06 f0 55 aa 52 08 02 39 00 00 40 00 00 02 d1 01 39 00 00 40 00 00 02 6f 08 39 00 00 40 00 00 07 d0 09 6a 08 3d 0a 18 39 00 00 40 00 00 06 f0 55 aa 52 08 07 39 00 00 40 00 00 02 d9 40 39 00 00 40 00 00 02 c0 01 39 00 00 40 00 00 03 51 07 ff 39 00 00 40 00 00 02 6f 01 39 00 00 40 00 00 05 88 02 62 09 8c 39 00 00 40 00 00 03 87 11 11 39 00 00 40 00 00 02 88 01 39 00 00 00 00 00 02 85 01];
                    mi,mdss-dsi-local-hbm-hlpm-white-1000nit-command-update = <0x87 0x14 0x02 0x51 0x11 0x02 0xd0 0x0d 0x06>;
                    mi,mdss-dsi-local-hbm-hlpm-white-1000nit-command-state = "dsi_hs_mode";
                    mi,mdss-dsi-local-hbm-normal-white-110nit-command = [39 00 00 40 00 00 06 f0 55 aa 52 08 00 39 00 00 40 00 00 02 6f 17 39 00 00 40 00 00 03 b2 07 ff 39 00 00 40 00 00 02 6f 1f 39 00 00 40 00 00 03 b2 00 50 39 00 00 40 00 00 06 f0 55 aa 52 08 02 39 00 00 40 00 00 02 d1 01 39 00 00 40 00 00 02 6f 08 39 00 00 40 00 00 07 d0 06 13 05 60 06 8f 39 00 00 40 00 00 06 f0 55 aa 52 08 07 39 00 00 40 00 00 02 d9 40 39 00 00 40 00 00 02 c0 01 39 00 00 40 00 00 03 51 07 ff 39 00 00 40 00 00 02 6f 01 39 00 00 40 00 00 05 88 02 62 09 8c 39 00 00 40 00 00 03 87 11 11 39 00 00 40 00 00 02 88 01 39 00 00 00 00 00 02 85 01];
                    mi,mdss-dsi-local-hbm-normal-white-110nit-command-update = <0x87 0x0f 0x02 0x51 0x0c 0x02 0xd0 0x08 0x06>;
                    mi,mdss-dsi-local-hbm-normal-white-110nit-command-state = "dsi_hs_mode";
                    mi,mdss-dsi-local-hbm-hlpm-white-110nit-command = [39 00 00 00 00 00 06 f0 55 aa 52 08 00 39 00 00 00 00 00 02 b2 98 39 00 00 00 00 00 02 65 00 39 00 00 00 32 00 01 38 39 00 00 00 00 00 01 2c 39 00 00 00 00 00 06 f0 55 aa 52 08 00 39 00 00 40 00 00 02 6f 17 39 00 00 40 00 00 03 b2 07 ff 39 00 00 40 00 00 02 6f 1f 39 00 00 40 00 00 03 b2 00 50 39 00 00 40 00 00 06 f0 55 aa 52 08 02 39 00 00 40 00 00 02 d1 01 39 00 00 40 00 00 02 6f 08 39 00 00 40 00 00 07 d0 06 13 05 60 06 8f 39 00 00 40 00 00 06 f0 55 aa 52 08 07 39 00 00 40 00 00 02 d9 40 39 00 00 40 00 00 02 c0 01 39 00 00 40 00 00 03 51 07 ff 39 00 00 40 00 00 02 6f 01 39 00 00 40 00 00 05 88 02 62 09 8c 39 00 00 40 00 00 03 87 11 11 39 00 00 40 00 00 02 88 01 39 00 00 00 00 00 02 85 01];
                    mi,mdss-dsi-local-hbm-hlpm-white-110nit-command-update = <0x87 0x14 0x02 0x51 0x11 0x02 0xd0 0x0d 0x06>;
                    mi,mdss-dsi-local-hbm-hlpm-white-110nit-command-state = "dsi_hs_mode";
                    mi,mdss-dsi-local-hbm-normal-green-500nit-command = [39 00 00 00 00 00 06 f0 55 aa 52 08 00 39 00 00 40 00 00 02 6f 17 39 00 00 40 00 00 03 b2 07 ff 39 00 00 40 00 00 02 6f 1f 39 00 00 40 00 00 03 b2 00 50 39 00 00 40 00 00 06 f0 55 aa 52 08 02 39 00 00 40 00 00 02 d1 01 39 00 00 40 00 00 02 6f 08 39 00 00 40 00 00 07 d0 00 00 07 f1 00 00 39 00 00 40 00 00 06 f0 55 aa 52 08 07 39 00 00 40 00 00 02 d9 40 39 00 00 40 00 00 02 c0 01 39 00 00 40 00 00 03 51 07 ff 39 00 00 40 00 00 02 6f 01 39 00 00 40 00 00 05 88 02 62 09 8c 39 00 00 40 00 00 03 87 11 11 39 00 00 40 00 00 02 88 01 39 00 00 00 00 00 02 85 01];
                    mi,mdss-dsi-local-hbm-normal-green-500nit-command-update = <0x87 0x0f 0x02 0x51 0x0c 0x02>;
                    mi,mdss-dsi-local-hbm-normal-green-500nit-command-state = "dsi_lp_mode";
                    mi,mdss-dsi-local-hbm-off-to-normal-command = [39 00 00 00 00 00 02 53 20 39 00 00 40 00 00 03 51 07 ff 39 00 00 40 00 00 03 87 0f ff 39 00 00 40 00 00 02 88 01 39 00 00 00 00 00 02 86 01];
                    mi,mdss-dsi-local-hbm-off-to-normal-command-update = <0x51 0x01 0x02>;
                    mi,mdss-dsi-local-hbm-off-to-normal-command-state = "dsi_hs_mode";
                    mi,mdss-dsi-local-hbm-off-to-hbm-command = [39 00 00 40 00 00 03 51 07 ff 39 00 00 40 00 00 03 87 0f ff 39 00 00 40 00 00 02 88 01 39 00 00 00 00 00 02 86 01];
                    mi,mdss-dsi-local-hbm-off-to-hbm-command-update = <0x51 0x00 0x02>;
                    mi,mdss-dsi-local-hbm-off-to-hbm-command-state = "dsi_hs_mode";
                    mi,mdss-dsi-local-hbm-off-to-hlpm-command = <0x39000040 0x351 0x3900 0x400000 0x3870fff 0x39000040 0x288 0x1390000 0x02 0x86011500 0x400000 0x25f0139 0x4000 0x55100 0xffe39 0x4000 0x6f055 0xaa520800 0x15000040 0x2b2 0x18150000 0x140002 0x39001500 0x400000 0x2650115 0x00 0x22c00>;
                    mi,mdss-dsi-local-hbm-off-to-hlpm-command-state = "dsi_hs_mode";
                    mi,mdss-dsi-local-hbm-off-to-llpm-command = <0x39000040 0x351 0x3900 0x400000 0x3870fff 0x39000040 0x288 0x1390000 0x02 0x86011500 0x400000 0x25f0139 0x4000 0x55100 0x15539 0x4000 0x6f055 0xaa520800 0x15000040 0x2b2 0x18150000 0x140002 0x39001500 0x400000 0x2650115 0x00 0x22c00>;
                    mi,mdss-dsi-local-hbm-off-to-llpm-command-state = "dsi_hs_mode";
                    mi,mdss-dsi-doze-hbm-command = [15 00 00 40 00 00 02 5f 01 39 00 00 40 00 00 05 51 00 00 0f fe 39 00 00 40 00 00 06 f0 55 aa 52 08 00 15 00 00 40 00 00 02 b2 18 15 00 00 00 14 00 02 39 00 15 00 00 40 00 00 02 65 01 15 00 00 00 00 00 02 2c 00];
                    mi,mdss-dsi-doze-hbm-command-state = "dsi_lp_mode";
                    mi,mdss-dsi-doze-lbm-command = [15 00 00 40 00 00 02 5f 01 39 00 00 40 00 00 05 51 00 00 01 55 39 00 00 40 00 00 06 f0 55 aa 52 08 00 15 00 00 40 00 00 02 b2 18 15 00 00 00 14 00 02 39 00 15 00 00 40 00 00 02 65 01 15 00 00 00 00 00 02 2c 00];
                    mi,mdss-dsi-doze-lbm-command-state = "dsi_lp_mode";
                    mi,mdss-dsi-doze-hbm-nolp-command = [39 00 00 00 00 00 06 f0 55 aa 52 08 00 39 00 00 00 00 00 02 b2 98 39 00 00 40 00 00 02 65 00 39 00 00 40 32 00 01 38 39 00 00 40 00 00 05 51 00 fc 0f fe 39 00 00 00 00 00 01 2c];
                    mi,mdss-dsi-doze-hbm-nolp-command-state = "dsi_lp_mode";
                    mi,mdss-dsi-doze-lbm-nolp-command = [39 00 00 00 00 00 06 f0 55 aa 52 08 00 39 00 00 00 00 00 02 b2 98 39 00 00 40 00 00 02 65 00 39 00 00 40 32 00 01 38 39 00 00 40 00 00 05 51 00 14 0f fe 39 00 00 00 00 00 01 2c];
                    mi,mdss-dsi-doze-lbm-nolp-command-state = "dsi_lp_mode";
                    mi,mdss-dsi-flat-mode-on-command = <0x15000000 0x22f 0x4150000 0x60000002 0x5f003900 0x600000 0x6f055aa 0x52080015 0x6000 0x26f0b 0x15000060 0x2c0 0x60390000 0x60000006 0xf055aa52 0x8021500 0x600000 0x2cc3015 0x2014 0x2ce01>;
                    mi,mdss-dsi-flat-mode-on-command-state = "dsi_lp_mode";
                    mi,mdss-dsi-flat-mode-on-sec-command = [39 00 00 00 00 00 06 f0 55 aa 52 08 02 15 00 00 00 00 00 02 cc 00];
                    mi,mdss-dsi-flat-mode-on-sec-command-state = "dsi_lp_mode";
                    mi,mdss-dsi-flat-mode-off-command = <0x15000000 0x22f 0x4150000 0x60000002 0x5f013900 0x600000 0x6f055aa 0x52080015 0x6000 0x26f0b 0x15000060 0x2c0 0x20390000 0x60000006 0xf055aa52 0x8021500 0x600000 0x2cc3015 0x2014 0x2ce01>;
                    mi,mdss-dsi-flat-mode-off-command-state = "dsi_lp_mode";
                    mi,mdss-dsi-flat-mode-off-sec-command = [39 00 00 00 00 00 06 f0 55 aa 52 08 02 15 00 00 00 00 00 02 cc 00];
                    mi,mdss-dsi-flat-mode-off-sec-command-state = "dsi_lp_mode";
                    mi,mdss-dsi-round-corner-on-command = [39 00 00 00 00 00 06 f0 55 aa 52 08 07 39 00 00 00 00 00 02 c0 01];
                    mi,mdss-dsi-round-corner-on-command-state = "dsi_lp_mode";
                    mi,mdss-dsi-round-corner-off-command = [39 00 00 00 00 00 06 f0 55 aa 52 08 07 39 00 00 00 00 00 02 c0 00];
                    mi,mdss-dsi-round-corner-off-command-state = "dsi_lp_mode";
                    qcom,mdss-dsi-panel-phy-timings = [00 24 0a 0a 1a 25 09 0a 09 02 04 00 1e 0f];
                    qcom,display-topology = <0x02 0x02 0x01>;
                    qcom,default-topology-index = <0x00>;
                };
                timing@1 {
                    qcom,mdss-dsi-cmd-mode;
                    qcom,mdss-dsi-panel-framerate = <0x78>;
                    qcom,mdss-dsi-panel-width = <0x4c4>;
                    qcom,mdss-dsi-panel-height = <0xa98>;
                    qcom,mdss-dsi-h-front-porch = <0x10>;
                    qcom,mdss-dsi-h-back-porch = <0x56>;
                    qcom,mdss-dsi-h-pulse-width = <0x10>;
                    qcom,mdss-dsi-h-sync-skew = <0x00>;
                    qcom,mdss-dsi-v-back-porch = <0x14>;
                    qcom,mdss-dsi-v-front-porch = <0x14>;
                    qcom,mdss-dsi-v-pulse-width = <0x04>;
                    qcom,mdss-dsi-h-sync-pulse = <0x00>;
                    qcom,mdss-dsi-h-left-border = <0x00>;
                    qcom,mdss-dsi-h-right-border = <0x00>;
                    qcom,mdss-dsi-v-top-border = <0x00>;
                    qcom,mdss-dsi-v-bottom-border = <0x00>;
                    qcom,mdss-dsi-panel-clockrate = <0x4190ab00>;
                    qcom,mdss-dsi-panel-jitter = <0x05 0x01>;
                    qcom,mdss-mdp-transfer-time-us = <0x1c84>;
                    qcom,mdss-dsi-on-command = <0x39000000 0x6f0 0x55aa5208 0x150000 0x40000002 0x6f061500 0x400000 0x2b52c15 0x4000 0x26f0c 0x15000000 0x2b5 0x2c390000 0x40000006 0xf055aa52 0x8033900 0x00 0x1eb00f00 0xf0002 0xf00000f 0xf00 0xf0000 0xf00000f 0xf00 0xf0039 0x4000 0x6f055 0xaa520805 0x39000040 0x4d0 0x71039 0x4000 0x5e000 0xa9e0239 0x4000 0x6f055 0xaa520806 0x39000040 0x6b1 0x32310f32 0x31150000 0x40000002 0xb30e3900 0x400000 0x6b73231 0xf323115 0x00 0x2b90e 0x39000040 0x5ff 0xaa55a580 0x15000040 0x26f 0x1d150000 0x40000002 0xf2053900 0x400000 0x6f055aa 0x52080015 0x4000 0x26f1c 0x39000040 0x4c0 0x3121139 0x4000 0x6f055 0xaa520800 0x15000000 0x203 0x1390000 0x05 0x3b001400 0x14150000 0x02 0x90113900 0x400000 0x1391ab28 0xcc200 0x2320131 0x808bb 0x77b10f0 0x15000000 0x22c 0x390000 0x40000005 0x5100000f 0xfe150000 0x02 0x53201500 0x00 0x2350039 0x4000 0x52a00 0x4c339 0x00 0x52b00 0xa9715 0x4000 0x22f03 0x15000040 0x25f 0x1390000 0x40000006 0xf055aa52 0x8001500 0x400000 0x26f0a15 0x4000 0x2c020 0x39000040 0x6f0 0x55aa5208 0x2150000 0x40000002 0xcc301500 0x1400 0x2ce0115 0x00 0x2cc00 0x39000040 0x6f0 0x55aa5208 0x1390000 0x08 0xc39b0194 0xd0220200 0x39000040 0x6f0 0x55aa5208 0x7390000 0x02 0xc0013900 0x400000 0x6f055aa 0x52080039 0x4000 0x26f05 0x39000000 0x2be 0x88390000 0x40000006 0xf055aa52 0x8001500 0x400000 0x26f0215 0x00 0x2c1d8 0x39000040 0x5ff 0xaa55a580 0x15000040 0x26f 0x61150000 0x02 0xf3803900 0x400000 0x6f055aa 0x52080415 0x4000 0x26f0d 0x15000000 0x2ca 0x5390100 0x40000006 0xf055aa52 0x8001501 0x400000 0x2b29815 0x1004000 0x26f02 0x39010000 0x3b2 0xa0a0500 0x7800 0x2110005 0x00 0x22900>;
                    qcom,mdss-dsi-off-command = [05 00 00 00 14 00 02 28 00 05 00 00 00 64 00 02 10 00];
                    qcom,mdss-dsi-on-command-state = "dsi_lp_mode";
                    qcom,mdss-dsi-off-command-state = "dsi_lp_mode";
                    qcom,mdss-dsi-timing-switch-command = <0x15000000 0x22f 0x3390000 0x40000006 0xf055aa52 0x8001500 0x400000 0x26f0a15 0x4000 0x2c020 0x39000040 0x6f0 0x55aa5208 0x2150000 0x40000002 0xcc301500 0xa00 0x2ce0115 0x00 0x2cc00>;
                    qcom,mdss-dsi-timing-switch-command-update = <0xc0 0x03 0x01>;
                    qcom,mdss-dsi-timing-switch-command-state = "dsi_hs_mode";
                    qcom,mdss-dsi-nolp-command = [39 00 00 00 00 00 06 f0 55 aa 52 08 00 39 00 00 00 00 00 02 b2 98 39 00 00 40 00 00 02 65 00 39 00 00 40 00 00 01 38 39 00 00 40 00 00 05 51 00 fc 0f fe 39 00 00 00 00 00 01 2c];
                    qcom,mdss-dsi-nolp-command-update = <0x51 0x04 0x02>;
                    qcom,mdss-dsi-nolp-command-state = "dsi_lp_mode";
                    qcom,compression-mode = "dsc";
                    qcom,mdss-dsc-config-by-manufacture-cmd;
                    qcom,mdss-dsc-version = <0x11>;
                    qcom,mdss-dsc-scr-version = <0x00>;
                    qcom,mdss-dsc-slice-height = <0x0c>;
                    qcom,mdss-dsc-slice-width = <0x262>;
                    qcom,mdss-dsc-slice-per-pkt = <0x02>;
                    qcom,mdss-dsc-bit-per-component = <0x0a>;
                    qcom,mdss-dsc-bit-per-pixel = <0x08>;
                    qcom,mdss-dsc-block-prediction-enable;
                    mi,mdss-flat-status-control-gamma-cfg = <0x60 0x20>;
                    mi,mdss-dsi-dimmingon-command = [39 00 00 00 00 00 02 53 28];
                    mi,mdss-dsi-dimmingon-command-state = "dsi_hs_mode";
                    mi,mdss-dsi-dimmingoff-command = [39 00 00 00 00 00 02 53 20];
                    mi,mdss-dsi-dimmingoff-command-state = "dsi_hs_mode";
                    mi,mdss-dsi-hbm-fod-on-command = [39 00 00 00 00 00 03 51 0f ff];
                    mi,mdss-dsi-hbm-fod-on-command-state = "dsi_lp_mode";
                    mi,mdss-dsi-hbm-fod-off-command = [39 00 00 00 00 00 03 51 07 ff];
                    mi,mdss-dsi-hbm-fod-off-command-state = "dsi_lp_mode";
                    mi,mdss-dsi-hbm-fod-off-command-update = <0x51 0x00 0x02>;
                    mi,mdss-dsi-local-hbm-normal-white-1000nit-command = [39 00 00 40 00 00 06 f0 55 aa 52 08 00 39 00 00 40 00 00 02 6f 17 39 00 00 40 00 00 03 b2 07 ff 39 00 00 40 00 00 02 6f 1f 39 00 00 40 00 00 03 b2 00 50 39 00 00 40 00 00 06 f0 55 aa 52 08 02 39 00 00 40 00 00 02 d1 01 39 00 00 40 00 00 02 6f 08 39 00 00 40 00 00 07 d0 09 6a 08 3d 0a 18 39 00 00 40 00 00 06 f0 55 aa 52 08 07 39 00 00 40 00 00 02 d9 40 39 00 00 40 00 00 02 c0 01 39 00 00 40 00 00 03 51 07 ff 39 00 00 40 00 00 02 6f 01 39 00 00 40 00 00 05 88 02 62 09 8c 39 00 00 40 00 00 03 87 11 11 39 00 00 40 00 00 02 88 01 39 00 00 00 00 00 02 85 01];
                    mi,mdss-dsi-local-hbm-normal-white-1000nit-command-update = <0x87 0x0f 0x02 0x51 0x0c 0x02 0xd0 0x08 0x06>;
                    mi,mdss-dsi-local-hbm-normal-white-1000nit-command-state = "dsi_hs_mode";
                    mi,mdss-dsi-local-hbm-hlpm-white-1000nit-command = [39 00 00 00 00 00 06 f0 55 aa 52 08 00 39 00 00 00 00 00 02 b2 98 39 00 00 00 00 00 02 65 00 39 00 00 00 32 00 02 38 00 39 00 00 00 00 00 02 2c 00 39 00 00 00 00 00 06 f0 55 aa 52 08 00 39 00 00 40 00 00 02 6f 17 39 00 00 40 00 00 03 b2 07 ff 39 00 00 40 00 00 02 6f 1f 39 00 00 40 00 00 03 b2 00 50 39 00 00 40 00 00 06 f0 55 aa 52 08 02 39 00 00 40 00 00 02 d1 01 39 00 00 40 00 00 02 6f 08 39 00 00 40 00 00 07 d0 09 6a 08 3d 0a 18 39 00 00 40 00 00 06 f0 55 aa 52 08 07 39 00 00 40 00 00 02 d9 40 39 00 00 40 00 00 02 c0 01 39 00 00 40 00 00 03 51 07 ff 39 00 00 40 00 00 02 6f 01 39 00 00 40 00 00 05 88 02 62 09 8c 39 00 00 40 00 00 03 87 11 11 39 00 00 40 00 00 02 88 01 39 00 00 00 00 00 02 85 01];
                    mi,mdss-dsi-local-hbm-hlpm-white-1000nit-command-update = <0x87 0x14 0x02 0x51 0x11 0x02 0xd0 0x0d 0x06>;
                    mi,mdss-dsi-local-hbm-hlpm-white-1000nit-command-state = "dsi_hs_mode";
                    mi,mdss-dsi-local-hbm-normal-white-110nit-command = [39 00 00 40 00 00 06 f0 55 aa 52 08 00 39 00 00 40 00 00 02 6f 17 39 00 00 40 00 00 03 b2 07 ff 39 00 00 40 00 00 02 6f 1f 39 00 00 40 00 00 03 b2 00 50 39 00 00 40 00 00 06 f0 55 aa 52 08 02 39 00 00 40 00 00 02 d1 01 39 00 00 40 00 00 02 6f 08 39 00 00 40 00 00 07 d0 06 13 05 60 06 8f 39 00 00 40 00 00 06 f0 55 aa 52 08 07 39 00 00 40 00 00 02 d9 40 39 00 00 40 00 00 02 c0 01 39 00 00 40 00 00 03 51 07 ff 39 00 00 40 00 00 02 6f 01 39 00 00 40 00 00 05 88 02 62 09 8c 39 00 00 40 00 00 03 87 11 11 39 00 00 40 00 00 02 88 01 39 00 00 00 00 00 02 85 01];
                    mi,mdss-dsi-local-hbm-normal-white-110nit-command-update = <0x87 0x0f 0x02 0x51 0x0c 0x02 0xd0 0x08 0x06>;
                    mi,mdss-dsi-local-hbm-normal-white-110nit-command-state = "dsi_hs_mode";
                    mi,mdss-dsi-local-hbm-hlpm-white-110nit-command = [39 00 00 00 00 00 06 f0 55 aa 52 08 00 39 00 00 00 00 00 02 b2 98 39 00 00 00 00 00 02 65 00 39 00 00 00 32 00 02 38 00 39 00 00 00 00 00 02 2c 00 39 00 00 00 00 00 06 f0 55 aa 52 08 00 39 00 00 40 00 00 02 6f 17 39 00 00 40 00 00 03 b2 07 ff 39 00 00 40 00 00 02 6f 1f 39 00 00 40 00 00 03 b2 00 50 39 00 00 40 00 00 06 f0 55 aa 52 08 02 39 00 00 40 00 00 02 d1 01 39 00 00 40 00 00 02 6f 08 39 00 00 40 00 00 07 d0 06 13 05 60 06 8f 39 00 00 40 00 00 06 f0 55 aa 52 08 07 39 00 00 40 00 00 02 d9 40 39 00 00 40 00 00 02 c0 01 39 00 00 40 00 00 03 51 07 ff 39 00 00 40 00 00 02 6f 01 39 00 00 40 00 00 05 88 02 62 09 8c 39 00 00 40 00 00 03 87 11 11 39 00 00 40 00 00 02 88 01 39 00 00 00 00 00 02 85 01];
                    mi,mdss-dsi-local-hbm-hlpm-white-110nit-command-update = <0x87 0x14 0x02 0x51 0x11 0x02 0xd0 0x0d 0x06>;
                    mi,mdss-dsi-local-hbm-hlpm-white-110nit-command-state = "dsi_hs_mode";
                    mi,mdss-dsi-local-hbm-normal-green-500nit-command = [39 00 00 00 00 00 06 f0 55 aa 52 08 00 39 00 00 40 00 00 02 6f 17 39 00 00 40 00 00 03 b2 07 ff 39 00 00 40 00 00 02 6f 1f 39 00 00 40 00 00 03 b2 00 50 39 00 00 40 00 00 06 f0 55 aa 52 08 02 39 00 00 40 00 00 02 d1 01 39 00 00 40 00 00 02 6f 08 39 00 00 40 00 00 07 d0 00 00 07 f1 00 00 39 00 00 40 00 00 06 f0 55 aa 52 08 07 39 00 00 40 00 00 02 d9 40 39 00 00 40 00 00 02 c0 01 39 00 00 40 00 00 03 51 07 ff 39 00 00 40 00 00 02 6f 01 39 00 00 40 00 00 05 88 02 62 09 8c 39 00 00 40 00 00 03 87 11 11 39 00 00 40 00 00 02 88 01 39 00 00 00 00 00 02 85 01];
                    mi,mdss-dsi-local-hbm-normal-green-500nit-command-update = <0x87 0x0f 0x02 0x51 0x0c 0x02>;
                    mi,mdss-dsi-local-hbm-normal-green-500nit-command-state = "dsi_lp_mode";
                    mi,mdss-dsi-local-hbm-off-to-normal-command = [39 00 00 00 00 00 02 53 20 39 00 00 40 00 00 03 51 07 ff 39 00 00 40 00 00 03 87 0f ff 39 00 00 40 00 00 02 88 01 39 00 00 00 00 00 02 86 01];
                    mi,mdss-dsi-local-hbm-off-to-normal-command-update = <0x51 0x01 0x02>;
                    mi,mdss-dsi-local-hbm-off-to-normal-command-state = "dsi_hs_mode";
                    mi,mdss-dsi-local-hbm-off-to-hbm-command = [39 00 00 40 00 00 03 51 07 ff 39 00 00 40 00 00 03 87 0f ff 39 00 00 40 00 00 02 88 01 39 00 00 00 00 00 02 86 01];
                    mi,mdss-dsi-local-hbm-off-to-hbm-command-update = <0x51 0x00 0x02>;
                    mi,mdss-dsi-local-hbm-off-to-hbm-command-state = "dsi_hs_mode";
                    mi,mdss-dsi-local-hbm-off-to-hlpm-command = <0x39000040 0x351 0x3900 0x400000 0x3870fff 0x39000040 0x288 0x1390000 0x02 0x86011500 0x400000 0x25f0139 0x4000 0x55100 0xffe39 0x4000 0x6f055 0xaa520800 0x15000040 0x2b2 0x18150000 0x140002 0x39001500 0x400000 0x2650115 0x00 0x22c00>;
                    mi,mdss-dsi-local-hbm-off-to-hlpm-command-state = "dsi_hs_mode";
                    mi,mdss-dsi-local-hbm-off-to-llpm-command = <0x39000040 0x351 0x3900 0x400000 0x3870fff 0x39000040 0x288 0x1390000 0x02 0x86011500 0x400000 0x25f0139 0x4000 0x55100 0x15539 0x4000 0x6f055 0xaa520800 0x15000040 0x2b2 0x18150000 0x140002 0x39001500 0x400000 0x2650115 0x00 0x22c00>;
                    mi,mdss-dsi-local-hbm-off-to-llpm-command-state = "dsi_hs_mode";
                    mi,mdss-dsi-doze-hbm-command = [15 00 00 40 00 00 02 5f 01 39 00 00 40 00 00 05 51 00 00 0f fe 39 00 00 40 00 00 06 f0 55 aa 52 08 00 15 00 00 40 00 00 02 b2 18 15 00 00 00 14 00 02 39 00 15 00 00 40 00 00 02 65 01 15 00 00 00 00 00 02 2c 00];
                    mi,mdss-dsi-doze-hbm-command-state = "dsi_lp_mode";
                    mi,mdss-dsi-doze-lbm-command = [15 00 00 40 00 00 02 5f 01 39 00 00 40 00 00 05 51 00 00 01 55 39 00 00 40 00 00 06 f0 55 aa 52 08 00 15 00 00 40 00 00 02 b2 18 15 00 00 00 14 00 02 39 00 15 00 00 40 00 00 02 65 01 15 00 00 00 00 00 02 2c 00];
                    mi,mdss-dsi-doze-lbm-command-state = "dsi_lp_mode";
                    mi,mdss-dsi-doze-hbm-nolp-command = [39 00 00 00 00 00 06 f0 55 aa 52 08 00 39 00 00 00 00 00 02 b2 98 39 00 00 40 00 00 02 65 00 39 00 00 40 32 00 01 38 39 00 00 40 00 00 05 51 00 fc 0f fe 39 00 00 00 00 00 01 2c];
                    mi,mdss-dsi-doze-hbm-nolp-command-state = "dsi_lp_mode";
                    mi,mdss-dsi-doze-lbm-nolp-command = [39 00 00 00 00 00 06 f0 55 aa 52 08 00 39 00 00 00 00 00 02 b2 98 39 00 00 40 00 00 02 65 00 39 00 00 40 32 00 01 38 39 00 00 40 00 00 05 51 00 14 0f fe 39 00 00 00 00 00 01 2c];
                    mi,mdss-dsi-doze-lbm-nolp-command-state = "dsi_lp_mode";
                    mi,mdss-dsi-flat-mode-on-command = <0x15000000 0x22f 0x3150000 0x60000002 0x5f003900 0x600000 0x6f055aa 0x52080015 0x6000 0x26f0a 0x15000060 0x2c0 0x60390000 0x60000006 0xf055aa52 0x8021500 0x600000 0x2cc3015 0x2014 0x2ce01>;
                    mi,mdss-dsi-flat-mode-on-command-state = "dsi_lp_mode";
                    mi,mdss-dsi-flat-mode-on-sec-command = [39 00 00 00 00 00 06 f0 55 aa 52 08 02 15 00 00 00 00 00 02 cc 00];
                    mi,mdss-dsi-flat-mode-on-sec-command-state = "dsi_lp_mode";
                    mi,mdss-dsi-flat-mode-off-command = <0x15000000 0x22f 0x3150000 0x60000002 0x5f013900 0x600000 0x6f055aa 0x52080015 0x6000 0x26f0a 0x15000060 0x2c0 0x20390000 0x60000006 0xf055aa52 0x8021500 0x600000 0x2cc3015 0x2014 0x2ce01>;
                    mi,mdss-dsi-flat-mode-off-command-state = "dsi_lp_mode";
                    mi,mdss-dsi-flat-mode-off-sec-command = [39 00 00 00 00 00 06 f0 55 aa 52 08 02 15 00 00 00 00 00 02 cc 00];
                    mi,mdss-dsi-flat-mode-off-sec-command-state = "dsi_lp_mode";
                    mi,mdss-dsi-round-corner-on-command = [39 00 00 00 00 00 06 f0 55 aa 52 08 07 39 00 00 00 00 00 02 c0 01];
                    mi,mdss-dsi-round-corner-on-command-state = "dsi_lp_mode";
                    mi,mdss-dsi-round-corner-off-command = [39 00 00 00 00 00 06 f0 55 aa 52 08 07 39 00 00 00 00 00 02 c0 00];
                    mi,mdss-dsi-round-corner-off-command-state = "dsi_lp_mode";
                    qcom,mdss-dsi-panel-phy-timings = [00 24 0a 0a 1a 25 09 0a 09 02 04 00 1e 0f];
                    qcom,display-topology = <0x02 0x02 0x01>;
                    qcom,default-topology-index = <0x00>;
                };
                timing@0 {
                    qcom,mdss-dsi-cmd-mode;
                    qcom,mdss-dsi-panel-framerate = <0x3c>;
                    qcom,mdss-dsi-panel-width = <0x4c4>;
                    qcom,mdss-dsi-panel-height = <0xa98>;
                    qcom,mdss-dsi-h-front-porch = <0x10>;
                    qcom,mdss-dsi-h-back-porch = <0x56>;
                    qcom,mdss-dsi-h-pulse-width = <0x10>;
                    qcom,mdss-dsi-h-sync-skew = <0x00>;
                    qcom,mdss-dsi-v-back-porch = <0x14>;
                    qcom,mdss-dsi-v-front-porch = <0x14>;
                    qcom,mdss-dsi-v-pulse-width = <0x04>;
                    qcom,mdss-dsi-h-sync-pulse = <0x00>;
                    qcom,mdss-dsi-h-left-border = <0x00>;
                    qcom,mdss-dsi-h-right-border = <0x00>;
                    qcom,mdss-dsi-v-top-border = <0x00>;
                    qcom,mdss-dsi-v-bottom-border = <0x00>;
                    qcom,mdss-dsi-panel-clockrate = <0x4190ab00>;
                    qcom,mdss-dsi-panel-jitter = <0x05 0x01>;
                    qcom,mdss-mdp-transfer-time-us = <0x1c84>;
                    qcom,mdss-dsi-on-command = <0x39000000 0x6f0 0x55aa5208 0x150000 0x40000002 0x6f061500 0x400000 0x2b52c15 0x4000 0x26f0c 0x15000000 0x2b5 0x2c390000 0x40000006 0xf055aa52 0x8033900 0x00 0x1eb00f00 0xf0002 0xf00000f 0xf00 0xf0000 0xf00000f 0xf00 0xf0039 0x4000 0x6f055 0xaa520805 0x39000040 0x4d0 0x71039 0x4000 0x5e000 0xa9e0239 0x4000 0x6f055 0xaa520806 0x39000040 0x6b1 0x32310f32 0x31150000 0x40000002 0xb30e3900 0x400000 0x6b73231 0xf323115 0x00 0x2b90e 0x39000040 0x5ff 0xaa55a580 0x15000040 0x26f 0x1d150000 0x40000002 0xf2053900 0x400000 0x6f055aa 0x52080015 0x4000 0x26f1c 0x39000040 0x4c0 0x3121139 0x4000 0x6f055 0xaa520800 0x15000000 0x203 0x1390000 0x05 0x3b001400 0x14150000 0x02 0x90113900 0x400000 0x1391ab28 0xcc200 0x2320131 0x808bb 0x77b10f0 0x15000000 0x22c 0x390000 0x40000005 0x5100000f 0xfe150000 0x02 0x53201500 0x00 0x2350039 0x4000 0x52a00 0x4c339 0x00 0x52b00 0xa9715 0x4000 0x22f02 0x15000040 0x25f 0x1390000 0x40000006 0xf055aa52 0x8001500 0x400000 0x26f0915 0x4000 0x2c000 0x39000040 0x6f0 0x55aa5208 0x2150000 0x40000002 0xcc301500 0x1400 0x2ce0115 0x00 0x2cc00 0x39000040 0x6f0 0x55aa5208 0x1390000 0x08 0xc39b0194 0xd0220200 0x39000040 0x6f0 0x55aa5208 0x7390000 0x02 0xc0013900 0x400000 0x6f055aa 0x52080039 0x4000 0x26f05 0x39000000 0x2be 0x88390000 0x40000006 0xf055aa52 0x8001500 0x400000 0x26f0215 0x00 0x2c1d8 0x39000040 0x5ff 0xaa55a580 0x15000040 0x26f 0x61150000 0x02 0xf3803900 0x400000 0x6f055aa 0x52080415 0x4000 0x26f0d 0x15000000 0x2ca 0x5390100 0x40000006 0xf055aa52 0x8001501 0x400000 0x2b29815 0x1004000 0x26f02 0x39010000 0x3b2 0xa0a0500 0x7800 0x2110005 0x00 0x22900>;
                    qcom,mdss-dsi-off-command = [05 00 00 00 14 00 02 28 00 05 00 00 00 64 00 02 10 00];
                    qcom,mdss-dsi-on-command-state = "dsi_lp_mode";
                    qcom,mdss-dsi-off-command-state = "dsi_lp_mode";
                    qcom,mdss-dsi-timing-switch-command = <0x15000000 0x22f 0x2390000 0x40000006 0xf055aa52 0x8001500 0x400000 0x26f0915 0x4000 0x2c000 0x39000040 0x6f0 0x55aa5208 0x2150000 0x40000002 0xcc301500 0x1400 0x2ce0115 0x00 0x2cc00>;
                    qcom,mdss-dsi-timing-switch-command-update = <0xc0 0x03 0x01>;
                    qcom,mdss-dsi-timing-switch-command-state = "dsi_hs_mode";
                    qcom,mdss-dsi-nolp-command = [39 00 00 00 00 00 06 f0 55 aa 52 08 00 39 00 00 00 00 00 02 b2 98 39 00 00 40 00 00 02 65 00 39 00 00 40 00 00 01 38 39 00 00 40 00 00 05 51 00 fc 0f fe 39 00 00 00 00 00 01 2c];
                    qcom,mdss-dsi-nolp-command-update = <0x51 0x04 0x02>;
                    qcom,mdss-dsi-nolp-command-state = "dsi_lp_mode";
                    qcom,compression-mode = "dsc";
                    qcom,mdss-dsc-config-by-manufacture-cmd;
                    qcom,mdss-dsc-version = <0x11>;
                    qcom,mdss-dsc-scr-version = <0x00>;
                    qcom,mdss-dsc-slice-height = <0x0c>;
                    qcom,mdss-dsc-slice-width = <0x262>;
                    qcom,mdss-dsc-slice-per-pkt = <0x02>;
                    qcom,mdss-dsc-bit-per-component = <0x0a>;
                    qcom,mdss-dsc-bit-per-pixel = <0x08>;
                    qcom,mdss-dsc-block-prediction-enable;
                    mi,mdss-flat-status-control-gamma-cfg = <0x40 0x00>;
                    mi,mdss-dsi-dimmingon-command = [39 00 00 00 00 00 02 53 28];
                    mi,mdss-dsi-dimmingon-command-state = "dsi_hs_mode";
                    mi,mdss-dsi-dimmingoff-command = [39 00 00 00 00 00 02 53 20];
                    mi,mdss-dsi-dimmingoff-command-state = "dsi_hs_mode";
                    mi,mdss-dsi-hbm-fod-on-command = [39 00 00 00 00 00 03 51 0f ff];
                    mi,mdss-dsi-hbm-fod-on-command-state = "dsi_lp_mode";
                    mi,mdss-dsi-hbm-fod-off-command = [39 00 00 00 00 00 03 51 07 ff];
                    mi,mdss-dsi-hbm-fod-off-command-state = "dsi_lp_mode";
                    mi,mdss-dsi-hbm-fod-off-command-update = <0x51 0x00 0x02>;
                    mi,mdss-dsi-local-hbm-normal-white-1000nit-command = [39 00 00 40 00 00 06 f0 55 aa 52 08 00 39 00 00 40 00 00 02 6f 17 39 00 00 40 00 00 03 b2 07 ff 39 00 00 40 00 00 02 6f 1f 39 00 00 40 00 00 03 b2 00 50 39 00 00 40 00 00 06 f0 55 aa 52 08 02 39 00 00 40 00 00 02 d1 01 39 00 00 40 00 00 02 6f 08 39 00 00 40 00 00 07 d0 09 6a 08 3d 0a 18 39 00 00 40 00 00 06 f0 55 aa 52 08 07 39 00 00 40 00 00 02 d9 40 39 00 00 40 00 00 02 c0 01 39 00 00 40 00 00 03 51 07 ff 39 00 00 40 00 00 02 6f 01 39 00 00 40 00 00 05 88 02 62 09 8c 39 00 00 40 00 00 03 87 11 11 39 00 00 40 00 00 02 88 01 39 00 00 00 00 00 02 85 01];
                    mi,mdss-dsi-local-hbm-normal-white-1000nit-command-update = <0x87 0x0f 0x02 0x51 0x0c 0x02 0xd0 0x08 0x06>;
                    mi,mdss-dsi-local-hbm-normal-white-1000nit-command-state = "dsi_hs_mode";
                    mi,mdss-dsi-local-hbm-hlpm-white-1000nit-command = [39 00 00 00 00 00 06 f0 55 aa 52 08 00 39 00 00 00 00 00 02 b2 98 39 00 00 00 00 00 02 65 00 39 00 00 00 32 00 02 38 00 39 00 00 00 00 00 02 2c 00 39 00 00 00 00 00 06 f0 55 aa 52 08 00 39 00 00 40 00 00 02 6f 17 39 00 00 40 00 00 03 b2 07 ff 39 00 00 40 00 00 02 6f 1f 39 00 00 40 00 00 03 b2 00 50 39 00 00 40 00 00 06 f0 55 aa 52 08 02 39 00 00 40 00 00 02 d1 01 39 00 00 40 00 00 02 6f 08 39 00 00 40 00 00 07 d0 09 6a 08 3d 0a 18 39 00 00 40 00 00 06 f0 55 aa 52 08 07 39 00 00 40 00 00 02 d9 40 39 00 00 40 00 00 02 c0 01 39 00 00 40 00 00 03 51 07 ff 39 00 00 40 00 00 02 6f 01 39 00 00 40 00 00 05 88 02 62 09 8c 39 00 00 40 00 00 03 87 11 11 39 00 00 40 00 00 02 88 01 39 00 00 00 00 00 02 85 01];
                    mi,mdss-dsi-local-hbm-hlpm-white-1000nit-command-update = <0x87 0x14 0x02 0x51 0x11 0x02 0xd0 0x0d 0x06>;
                    mi,mdss-dsi-local-hbm-hlpm-white-1000nit-command-state = "dsi_hs_mode";
                    mi,mdss-dsi-local-hbm-normal-white-110nit-command = [39 00 00 40 00 00 06 f0 55 aa 52 08 00 39 00 00 40 00 00 02 6f 17 39 00 00 40 00 00 03 b2 07 ff 39 00 00 40 00 00 02 6f 1f 39 00 00 40 00 00 03 b2 00 50 39 00 00 40 00 00 06 f0 55 aa 52 08 02 39 00 00 40 00 00 02 d1 01 39 00 00 40 00 00 02 6f 08 39 00 00 40 00 00 07 d0 06 13 05 60 06 8f 39 00 00 40 00 00 06 f0 55 aa 52 08 07 39 00 00 40 00 00 02 d9 40 39 00 00 40 00 00 02 c0 01 39 00 00 40 00 00 03 51 07 ff 39 00 00 40 00 00 02 6f 01 39 00 00 40 00 00 05 88 02 62 09 8c 39 00 00 40 00 00 03 87 11 11 39 00 00 40 00 00 02 88 01 39 00 00 00 00 00 02 85 01];
                    mi,mdss-dsi-local-hbm-normal-white-110nit-command-update = <0x87 0x0f 0x02 0x51 0x0c 0x02 0xd0 0x08 0x06>;
                    mi,mdss-dsi-local-hbm-normal-white-110nit-command-state = "dsi_hs_mode";
                    mi,mdss-dsi-local-hbm-hlpm-white-110nit-command = [39 00 00 00 00 00 06 f0 55 aa 52 08 00 39 00 00 00 00 00 02 b2 98 39 00 00 00 00 00 02 65 00 39 00 00 00 32 00 02 38 00 39 00 00 00 00 00 02 2c 00 39 00 00 00 00 00 06 f0 55 aa 52 08 00 39 00 00 40 00 00 02 6f 17 39 00 00 40 00 00 03 b2 07 ff 39 00 00 40 00 00 02 6f 1f 39 00 00 40 00 00 03 b2 00 50 39 00 00 40 00 00 06 f0 55 aa 52 08 02 39 00 00 40 00 00 02 d1 01 39 00 00 40 00 00 02 6f 08 39 00 00 40 00 00 07 d0 06 13 05 60 06 8f 39 00 00 40 00 00 06 f0 55 aa 52 08 07 39 00 00 40 00 00 02 d9 40 39 00 00 40 00 00 02 c0 01 39 00 00 40 00 00 03 51 07 ff 39 00 00 40 00 00 02 6f 01 39 00 00 40 00 00 05 88 02 62 09 8c 39 00 00 40 00 00 03 87 11 11 39 00 00 40 00 00 02 88 01 39 00 00 00 00 00 02 85 01];
                    mi,mdss-dsi-local-hbm-hlpm-white-110nit-command-update = <0x87 0x14 0x02 0x51 0x11 0x02 0xd0 0x0d 0x06>;
                    mi,mdss-dsi-local-hbm-hlpm-white-110nit-command-state = "dsi_hs_mode";
                    mi,mdss-dsi-local-hbm-normal-green-500nit-command = [39 00 00 00 00 00 06 f0 55 aa 52 08 00 39 00 00 40 00 00 02 6f 17 39 00 00 40 00 00 03 b2 07 ff 39 00 00 40 00 00 02 6f 1f 39 00 00 40 00 00 03 b2 00 50 39 00 00 40 00 00 06 f0 55 aa 52 08 02 39 00 00 40 00 00 02 d1 01 39 00 00 40 00 00 02 6f 08 39 00 00 40 00 00 07 d0 00 00 07 f1 00 00 39 00 00 40 00 00 06 f0 55 aa 52 08 07 39 00 00 40 00 00 02 d9 40 39 00 00 40 00 00 02 c0 01 39 00 00 40 00 00 03 51 07 ff 39 00 00 40 00 00 02 6f 01 39 00 00 40 00 00 05 88 02 62 09 8c 39 00 00 40 00 00 03 87 11 11 39 00 00 40 00 00 02 88 01 39 00 00 00 00 00 02 85 01];
                    mi,mdss-dsi-local-hbm-normal-green-500nit-command-update = <0x87 0x0f 0x02 0x51 0x0c 0x02>;
                    mi,mdss-dsi-local-hbm-normal-green-500nit-command-state = "dsi_lp_mode";
                    mi,mdss-dsi-local-hbm-off-to-normal-command = [39 00 00 00 00 00 02 53 20 39 00 00 40 00 00 03 51 07 ff 39 00 00 40 00 00 03 87 0f ff 39 00 00 40 00 00 02 88 01 39 00 00 00 00 00 02 86 01];
                    mi,mdss-dsi-local-hbm-off-to-normal-command-update = <0x51 0x01 0x02>;
                    mi,mdss-dsi-local-hbm-off-to-normal-command-state = "dsi_hs_mode";
                    mi,mdss-dsi-local-hbm-off-to-hbm-command = [39 00 00 40 00 00 03 51 07 ff 39 00 00 40 00 00 03 87 0f ff 39 00 00 40 00 00 02 88 01 39 00 00 00 00 00 02 86 01];
                    mi,mdss-dsi-local-hbm-off-to-hbm-command-update = <0x51 0x00 0x02>;
                    mi,mdss-dsi-local-hbm-off-to-hbm-command-state = "dsi_hs_mode";
                    mi,mdss-dsi-local-hbm-off-to-hlpm-command = <0x39000040 0x351 0x3900 0x400000 0x3870fff 0x39000040 0x288 0x1390000 0x02 0x86011500 0x400000 0x25f0139 0x4000 0x55100 0xffe39 0x4000 0x6f055 0xaa520800 0x15000040 0x2b2 0x18150000 0x140002 0x39001500 0x400000 0x2650115 0x00 0x22c00>;
                    mi,mdss-dsi-local-hbm-off-to-hlpm-command-state = "dsi_hs_mode";
                    mi,mdss-dsi-local-hbm-off-to-llpm-command = <0x39000040 0x351 0x3900 0x400000 0x3870fff 0x39000040 0x288 0x1390000 0x02 0x86011500 0x400000 0x25f0139 0x4000 0x55100 0x15539 0x4000 0x6f055 0xaa520800 0x15000040 0x2b2 0x18150000 0x140002 0x39001500 0x400000 0x2650115 0x00 0x22c00>;
                    mi,mdss-dsi-local-hbm-off-to-llpm-command-state = "dsi_hs_mode";
                    mi,mdss-dsi-doze-hbm-command = [15 00 00 40 00 00 02 5f 01 39 00 00 40 00 00 05 51 00 00 0f fe 39 00 00 40 00 00 06 f0 55 aa 52 08 00 15 00 00 40 00 00 02 b2 18 15 00 00 00 14 00 02 39 00 15 00 00 40 00 00 02 65 01 15 00 00 00 00 00 02 2c 00];
                    mi,mdss-dsi-doze-hbm-command-state = "dsi_lp_mode";
                    mi,mdss-dsi-doze-lbm-command = [15 00 00 40 00 00 02 5f 01 39 00 00 40 00 00 05 51 00 00 01 55 39 00 00 40 00 00 06 f0 55 aa 52 08 00 15 00 00 40 00 00 02 b2 18 15 00 00 00 14 00 02 39 00 15 00 00 40 00 00 02 65 01 15 00 00 00 00 00 02 2c 00];
                    mi,mdss-dsi-doze-lbm-command-state = "dsi_lp_mode";
                    mi,mdss-dsi-doze-hbm-nolp-command = [39 00 00 00 00 00 06 f0 55 aa 52 08 00 39 00 00 00 00 00 02 b2 98 39 00 00 40 00 00 02 65 00 39 00 00 40 32 00 01 38 39 00 00 40 00 00 05 51 00 fc 0f fe 39 00 00 00 00 00 01 2c];
                    mi,mdss-dsi-doze-hbm-nolp-command-state = "dsi_lp_mode";
                    mi,mdss-dsi-doze-lbm-nolp-command = [39 00 00 00 00 00 06 f0 55 aa 52 08 00 39 00 00 00 00 00 02 b2 98 39 00 00 40 00 00 02 65 00 39 00 00 40 32 00 01 38 39 00 00 40 00 00 05 51 00 14 0f fe 39 00 00 00 00 00 01 2c];
                    mi,mdss-dsi-doze-lbm-nolp-command-state = "dsi_lp_mode";
                    mi,mdss-dsi-flat-mode-on-command = <0x15000000 0x22f 0x2150000 0x60000002 0x5f003900 0x600000 0x6f055aa 0x52080015 0x6000 0x26f09 0x15000060 0x2c0 0x40390000 0x60000006 0xf055aa52 0x8021500 0x600000 0x2cc3015 0x2014 0x2ce01>;
                    mi,mdss-dsi-flat-mode-on-command-state = "dsi_lp_mode";
                    mi,mdss-dsi-flat-mode-on-sec-command = [39 00 00 00 00 00 06 f0 55 aa 52 08 02 15 00 00 00 00 00 02 cc 00];
                    mi,mdss-dsi-flat-mode-on-sec-command-state = "dsi_lp_mode";
                    mi,mdss-dsi-flat-mode-off-command = <0x15000000 0x22f 0x2150000 0x60000002 0x5f013900 0x600000 0x6f055aa 0x52080015 0x6000 0x26f09 0x15000060 0x2c0 0x390000 0x60000006 0xf055aa52 0x8021500 0x600000 0x2cc3015 0x2014 0x2ce01>;
                    mi,mdss-dsi-flat-mode-off-command-state = "dsi_lp_mode";
                    mi,mdss-dsi-flat-mode-off-sec-command = [39 00 00 00 00 00 06 f0 55 aa 52 08 02 15 00 00 00 00 00 02 cc 00];
                    mi,mdss-dsi-flat-mode-off-sec-command-state = "dsi_lp_mode";
                    mi,mdss-dsi-round-corner-on-command = [39 00 00 00 00 00 06 f0 55 aa 52 08 07 39 00 00 00 00 00 02 c0 01];
                    mi,mdss-dsi-round-corner-on-command-state = "dsi_lp_mode";
                    mi,mdss-dsi-round-corner-off-command = [39 00 00 00 00 00 06 f0 55 aa 52 08 07 39 00 00 00 00 00 02 c0 00];
                    mi,mdss-dsi-round-corner-off-command-state = "dsi_lp_mode";
                    qcom,mdss-dsi-panel-phy-timings = [00 24 0a 0a 1a 25 09 0a 09 02 04 00 1e 0f];
                    qcom,display-topology = <0x02 0x02 0x01>;
                    qcom,default-topology-index = <0x00>;
                };
            };
        };
    };

    fingerprint_goodix {
        status = "ok";
        goodix,gpio-irq = <&tlmm 0x28 0x00>;
        goodix,gpio-reset = <&tlmm 0x29 0x00>;
        compatible = "goodix,fingerprint";
    };

    ssusb@a600000 {
        usb-role-switch;
        compatible = "qcom,dwc-usb3-msm";
        reg = <0x0 0xa600000 0x0 0x100000>;
        reg-names = "core_base";
        #address-cells = <0x01>;
        #size-cells = <0x01>;
        ranges = <0xa600000 0x0 0xa600000 0x100000>;
        qcom,use-pdc-interrupts;
        qcom,use-eusb2-phy;
        qcom,dis-sending-cm-l1-quirk;
        qcom,core-clk-rate = <0xbebc200>;
        qcom,core-clk-rate-disconnected = <0x7f28155>;
        qcom,core-clk-rate-hs = <0x3f940ab>;
        qcom,pm-qos-latency = <0x02>;
        qcom,num-gsi-evt-buffs = <0x03>;
        qcom,gsi-reg-offset = <0xfc 0x110 0x120 0x130 0x144 0x1a4>;
        dwc3@a600000 {
            usb-role-switch;
            compatible = "snps,dwc3";
            reg = <0xa600000 0xd93c>;
            qcom,iommu-dma = "atomic";
            qcom,iommu-dma-addr-pool = <0x90000000 0x60000000>;
            dma-coherent;
            interrupts = <0x00 0x85 0x04>;
            snps,disable-clk-gating;
            snps,has-lpm-erratum;
            snps,hird-threshold = [00];
            snps,is-utmi-l1-suspend;
            snps,usb2-gadget-lpm-disable;
            snps,dis_u2_susphy_quirk;
            snps,dis_u3_susphy_quirk;
            snps,ssp-u3-u0-quirk;
            tx-fifo-resize;
            dr_mode = "otg";
            maximum-speed = "high-speed";
        };
    };

    qcom,pmic_glink {
        compatible = "qcom,pmic-glink";
        qcom,pmic-glink-channel = "PMIC_RTR_ADSP_APPS";
        qcom,subsys-name = "lpass";
        qcom,protection-domain = "tms/servreg", "msm/adsp/charger_pd";
        qcom,battery_charger {
            qcom,shutdown-voltage = <0xd16>;
            qcom,wireless-fw-name = "idt9415.bin";
            qcom,thermal-mitigation = <0x2dc6c0 0x16e360 0xf4240 0x7a120>;
            compatible = "qcom,battery-charger";
        };
    };
};

/* UFS: the ADT generator reads three board properties from this node
   (make-diting-adt-ipados18.py: diting,gcc-ufs-page, diting,smmu-stream-id, diting,ufs-spi).
   Values cross-checked against the stock diting tree (merged /soc/ufshc@1d84000):
   interrupts = <0x00 0x109 0x04> gives SPI 265, iommus = <.. 0xe0 ..> gives stream id
   0xe0, and 0x187000 is the SM8475 GCC UFS page register the Diting port uses. */
&ufs {
    status = "okay";
    reg = <0x0 0x1d84000 0x0 0x3000>,
          <0x0 0x1d88000 0x0 0x8000>,
          <0x0 0x1d90000 0x0 0x9000>;
    reg-names = "ufs_mem", "ufs_ice", "ufs_ice_hwkm";
    interrupt-parent = <&gic>;
    interrupts = <0 0x109 4>;
    /* 当前 NativeUfs 轮询完成；标准中断映射待完整验证。 */
    unixnu,adt-no-interrupts;
    unixnu,adt-u64 = "diting,ufs-hc-base", "diting,ufs-hc-size", "diting,gcc-ufs-page",
                     "diting,smmu-base", "diting,smmu-size";
    unixnu,adt-u32 = "diting,smmu-stream-id", "diting,smmu-context-banks",
                     "diting,smmu-match-groups", "diting,ufs-spi";
    diting,ufs-hc-base = /bits/ 64 <0x1d84000>;
    diting,ufs-hc-size = /bits/ 64 <0x3000>;
    diting,gcc-ufs-page = /bits/ 64 <0x187000>;
    diting,smmu-stream-id = <0xe0>;
    diting,smmu-base = /bits/ 64 <0x15000000>;
    diting,smmu-size = /bits/ 64 <0x100000>;
    diting,smmu-context-banks = <78>;
    /* 该值继承自同 SoC 的 Diting，尚未通过 Diting 寄存器核实。 */
    diting,smmu-match-groups = <120>;
    diting,ufs-spi = <265>;
};

/* Diting bring-up: ArmCpu starts the secondaries through its own path. The
   official ADT generator exports every enabled DTS CPU and adds /psci for
   more than one; the validated B1 ADT carries a single boot CPU and no /psci,
   and AppleARMCPU must not match sibling cpu nodes. Keep them disabled here so
   the tree stays the topology the board boots with. */
&cpu1 { status = "disabled"; };
&cpu2 { status = "disabled"; };
&cpu3 { status = "disabled"; };
&cpu4 { status = "disabled"; };
&cpu5 { status = "disabled"; };
&cpu6 { status = "disabled"; };
&cpu7 { status = "disabled"; };
